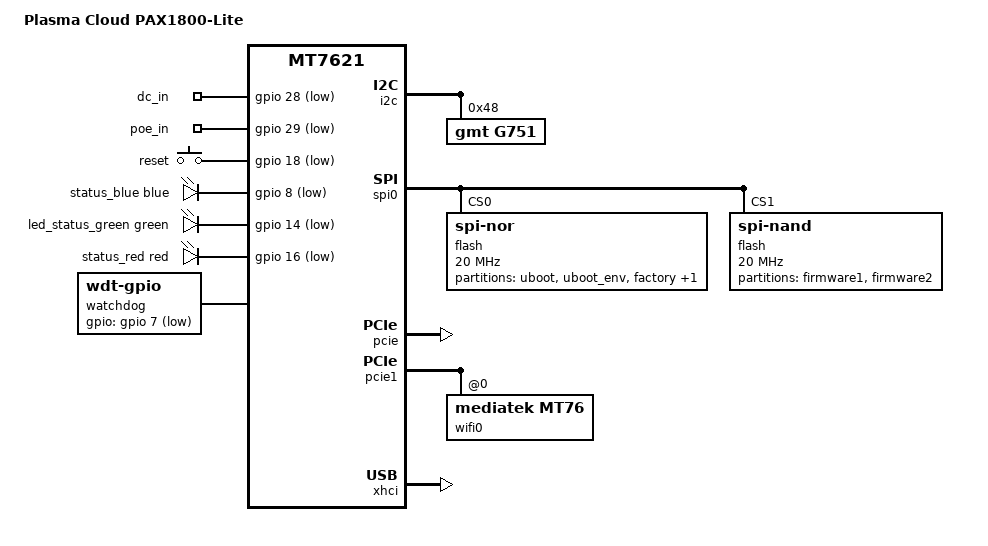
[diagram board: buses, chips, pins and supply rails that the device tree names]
// SPDX-License-Identifier: GPL-2.0-or-later OR MIT

#include "mt7621.dtsi"

#include <dt-bindings/gpio/gpio.h>
#include <dt-bindings/input/input.h>
#include <dt-bindings/leds/common.h>

/ {
	compatible = "plasmacloud,pax1800-lite", "mediatek,mt7621-soc";
	model = "Plasma Cloud PAX1800-Lite";

	chosen {
		bootargs = "console=ttyS0,115200";
	};

	aliases {
		led-boot = &led_status_green;
		led-failsafe = &led_status_green;
		led-running = &led_status_green;
		led-upgrade = &led_status_green;
		label-mac-device = &gmac1;
	};

	gpio_export {
		compatible = "gpio-export";
		#size-cells = <0>;

		dc_in {
			gpio-export,name = "dc_in";
			gpios = <&gpio 28 GPIO_ACTIVE_LOW>;
		};

		poe_in {
			gpio-export,name = "poe_in";
			gpios = <&gpio 29 GPIO_ACTIVE_LOW>;
		};
	};

	keys {
		compatible = "gpio-keys";

		reset {
			label = "reset";
			gpios = <&gpio 18 GPIO_ACTIVE_LOW>;
			linux,code = <KEY_RESTART>;
		};
	};

	leds {
		compatible = "gpio-leds";

		status_blue {
			color = <LED_COLOR_ID_BLUE>;
			function = LED_FUNCTION_STATUS;
			gpios = <&gpio 8 GPIO_ACTIVE_LOW>;
		};

		led_status_green: status_green {
			color = <LED_COLOR_ID_GREEN>;
			function = LED_FUNCTION_STATUS;
			gpios = <&gpio 14 GPIO_ACTIVE_LOW>;
		};

		status_red {
			color = <LED_COLOR_ID_RED>;
			function = LED_FUNCTION_STATUS;
			gpios = <&gpio 16 GPIO_ACTIVE_LOW>;
		};
	};

	watchdog {
		compatible = "linux,wdt-gpio";
		gpios = <&gpio 7 GPIO_ACTIVE_LOW>;
		hw_algo = "toggle";
		/* hw_margin_ms is actually 300s but driver limits it to 60s */
		hw_margin_ms = <60000>;
		always-running;
	};
};

&i2c {
	status = "okay";

	g751: g751@48 {
		compatible = "gmt,g751";
		reg = <0x48>;
		status = "okay";
	};
};

&spi0 {
	status = "okay";
	num-cs = <2>;

	flash@0 {
		#address-cells = <1>;
		#size-cells = <1>;
		compatible = "jedec,spi-nor";
		spi-max-frequency = <20000000>;
		reg = <0>;

		partitions {
			compatible = "fixed-partitions";
			#address-cells = <1>;
			#size-cells = <1>;

			partition@0 {
				label = "uboot";
				reg = <0x00000 0x80000>;
			};

			partition@80000 {
				label = "uboot_env";
				reg = <0x80000 0x10000>;
			};

			partition@90000 {
				label = "factory";
				reg = <0x90000 0x80000>;

				nvmem-layout {
					compatible = "fixed-layout";
					#address-cells = <1>;
					#size-cells = <1>;

					eeprom_factory_0: eeprom@0 {
						reg = <0x0 0xe00>;
					};

					macaddr_factory_3fff4: macaddr@3fff4 {
						reg = <0x3fff4 0x6>;
					};
				};
			};

			partition@110000 {
				label = "keys";
				reg = <0x110000 0x10000>;
			};

			/* 0x120000 - 0x200000 unused */
		};
	};

	flash@1 {
		compatible = "spi-nand";
		spi-max-frequency = <20000000>;
		reg = <1>;

		partitions {
			compatible = "fixed-partitions";
			#address-cells = <1>;
			#size-cells = <1>;

			partition@0 {
				label = "firmware1";
				reg = <0x0 0x4000000>;
				compatible = "linux,ubi";
			};

			partition@4000000 {
				label = "firmware2";
				reg = <0x4000000 0x4000000>;
				compatible = "linux,ubi";
			};
		};
	};
};

&pcie {
	status = "okay";
};

&pcie1 {
	wifi0: wifi@0,0 {
		compatible = "mediatek,mt76";
		reg = <0x0000 0 0 0 0>;

		nvmem-cells = <&eeprom_factory_0>;
		nvmem-cell-names = "eeprom";

		mediatek,disable-radar-background;

		power-limits {
			r0 {
				country = "CA";

				txpower-2g {
					b0 {
						channels = <1 1>;
						rates-cck =
							/bits/ 8 <40 40 40 40>;
						rates-ofdm =
							/bits/ 8 <36 36 36 36 36 36 36 36>;
						rates-mcs =
							/bits/ 8 <1 34 34 34 34 34 34 34 34 34 34>,
							/bits/ 8 <1 33 33 33 33 33 33 33 33 33 33>,
							/bits/ 8 <2 60 60 60 60 60 60 60 60 60 60>;
						rates-ru =
							/bits/ 8 <4 34 34 34 34 34 34 34 34 34 34 34 34>,
							/bits/ 8 <1 33 33 33 33 33 33 33 33 33 33 33 33>,
							/bits/ 8 <2 60 60 60 60 60 60 60 60 60 60 60 60>;
						paths-cck =
							/bits/ 8 <40 40 60 60>;
						paths-ofdm =
							/bits/ 8 <36 36 60 60>;
						paths-ofdm-bf =
							/bits/ 8 <36 36 60 60>;
						paths-ru =
							/bits/ 8 <4 34 34 60 60 34 60 60 60 60 60>,
							/bits/ 8 <1 33 33 60 60 33 60 60 60 60 60>,
							/bits/ 8 <2 60 60 60 60 60 60 60 60 60 60>;
						paths-ru-bf =
							/bits/ 8 <4 34 34 60 60 34 60 60 60 60 60>,
							/bits/ 8 <1 33 33 60 60 33 60 60 60 60 60>,
							/bits/ 8 <2 60 60 60 60 60 60 60 60 60 60>;
					};
					b1 {
						channels = <2 2>;
						rates-cck =
							/bits/ 8 <40 40 40 40>;
						rates-ofdm =
							/bits/ 8 <37 37 37 37 37 37 37 37>;
						rates-mcs =
							/bits/ 8 <1 34 34 34 34 34 34 34 34 34 34>,
							/bits/ 8 <1 33 33 33 33 33 33 33 33 33 33>,
							/bits/ 8 <2 60 60 60 60 60 60 60 60 60 60>;
						rates-ru =
							/bits/ 8 <4 34 34 34 34 34 34 34 34 34 34 34 34>,
							/bits/ 8 <1 33 33 33 33 33 33 33 33 33 33 33 33>,
							/bits/ 8 <2 60 60 60 60 60 60 60 60 60 60 60 60>;
						paths-cck =
							/bits/ 8 <40 40 60 60>;
						paths-ofdm =
							/bits/ 8 <37 37 60 60>;
						paths-ofdm-bf =
							/bits/ 8 <37 37 60 60>;
						paths-ru =
							/bits/ 8 <4 34 34 60 60 34 60 60 60 60 60>,
							/bits/ 8 <1 33 33 60 60 33 60 60 60 60 60>,
							/bits/ 8 <2 60 60 60 60 60 60 60 60 60 60>;
						paths-ru-bf =
							/bits/ 8 <4 34 34 60 60 34 60 60 60 60 60>,
							/bits/ 8 <1 33 33 60 60 33 60 60 60 60 60>,
							/bits/ 8 <2 60 60 60 60 60 60 60 60 60 60>;
					};
					b2 {
						channels = <3 6>;
						rates-cck =
							/bits/ 8 <40 40 40 40>;
						rates-ofdm =
							/bits/ 8 <40 40 40 40 40 40 40 40>;
						rates-mcs =
							/bits/ 8 <1 40 40 40 40 40 40 40 40 40 40>,
							/bits/ 8 <1 33 33 33 33 33 33 33 33 33 33>,
							/bits/ 8 <2 60 60 60 60 60 60 60 60 60 60>;
						rates-ru =
							/bits/ 8 <4 40 40 40 40 40 40 40 40 40 40 40 40>,
							/bits/ 8 <1 33 33 33 33 33 33 33 33 33 33 33 33>,
							/bits/ 8 <2 60 60 60 60 60 60 60 60 60 60 60 60>;
						paths-cck =
							/bits/ 8 <40 40 60 60>;
						paths-ofdm =
							/bits/ 8 <40 40 60 60>;
						paths-ofdm-bf =
							/bits/ 8 <40 40 60 60>;
						paths-ru =
							/bits/ 8 <4 40 40 60 60 40 60 60 60 60 60>,
							/bits/ 8 <1 33 33 60 60 33 60 60 60 60 60>,
							/bits/ 8 <2 60 60 60 60 60 60 60 60 60 60>;
						paths-ru-bf =
							/bits/ 8 <4 40 40 60 60 40 60 60 60 60 60>,
							/bits/ 8 <1 33 33 60 60 33 60 60 60 60 60>,
							/bits/ 8 <2 60 60 60 60 60 60 60 60 60 60>;
					};
					b3 {
						channels = <7 9>;
						rates-cck =
							/bits/ 8 <40 40 40 40>;
						rates-ofdm =
							/bits/ 8 <40 40 40 40 40 40 40 40>;
						rates-mcs =
							/bits/ 8 <1 40 40 40 40 40 40 40 40 40 40>,
							/bits/ 8 <1 32 32 32 32 32 32 32 32 32 32>,
							/bits/ 8 <2 60 60 60 60 60 60 60 60 60 60>;
						rates-ru =
							/bits/ 8 <4 40 40 40 40 40 40 40 40 40 40 40 40>,
							/bits/ 8 <1 32 32 32 32 32 32 32 32 32 32 32 32>,
							/bits/ 8 <2 60 60 60 60 60 60 60 60 60 60 60 60>;
						paths-cck =
							/bits/ 8 <40 40 60 60>;
						paths-ofdm =
							/bits/ 8 <40 40 60 60>;
						paths-ofdm-bf =
							/bits/ 8 <40 40 60 60>;
						paths-ru =
							/bits/ 8 <4 40 40 60 60 40 60 60 60 60 60>,
							/bits/ 8 <1 32 32 60 60 32 60 60 60 60 60>,
							/bits/ 8 <2 60 60 60 60 60 60 60 60 60 60>;
						paths-ru-bf =
							/bits/ 8 <4 40 40 60 60 40 60 60 60 60 60>,
							/bits/ 8 <1 32 32 60 60 32 60 60 60 60 60>,
							/bits/ 8 <2 60 60 60 60 60 60 60 60 60 60>;
					};
					b4 {
						channels = <10 10>;
						rates-cck =
							/bits/ 8 <40 40 40 40>;
						rates-ofdm =
							/bits/ 8 <38 38 38 38 38 38 38 38>;
						rates-mcs =
							/bits/ 8 <1 36 36 36 36 36 36 36 36 36 36>,
							/bits/ 8 <1 32 32 32 32 32 32 32 32 32 32>,
							/bits/ 8 <2 60 60 60 60 60 60 60 60 60 60>;
						rates-ru =
							/bits/ 8 <4 36 36 36 36 36 36 36 36 36 36 36 36>,
							/bits/ 8 <1 32 32 32 32 32 32 32 32 32 32 32 32>,
							/bits/ 8 <2 60 60 60 60 60 60 60 60 60 60 60 60>;
						paths-cck =
							/bits/ 8 <40 40 60 60>;
						paths-ofdm =
							/bits/ 8 <38 38 60 60>;
						paths-ofdm-bf =
							/bits/ 8 <38 38 60 60>;
						paths-ru =
							/bits/ 8 <4 36 36 60 60 36 60 60 60 60 60>,
							/bits/ 8 <1 32 32 60 60 32 60 60 60 60 60>,
							/bits/ 8 <2 60 60 60 60 60 60 60 60 60 60>;
						paths-ru-bf =
							/bits/ 8 <4 36 36 60 60 36 60 60 60 60 60>,
							/bits/ 8 <1 32 32 60 60 32 60 60 60 60 60>,
							/bits/ 8 <2 60 60 60 60 60 60 60 60 60 60>;
					};
					b5 {
						channels = <11 11>;
						rates-cck =
							/bits/ 8 <40 40 40 40>;
						rates-ofdm =
							/bits/ 8 <35 35 35 35 35 35 35 35>;
						rates-mcs =
							/bits/ 8 <1 33 33 33 33 33 33 33 33 33 33>,
							/bits/ 8 <1 32 32 32 32 32 32 32 32 32 32>,
							/bits/ 8 <2 60 60 60 60 60 60 60 60 60 60>;
						rates-ru =
							/bits/ 8 <4 33 33 33 33 33 33 33 33 33 33 33 33>,
							/bits/ 8 <1 32 32 32 32 32 32 32 32 32 32 32 32>,
							/bits/ 8 <2 60 60 60 60 60 60 60 60 60 60 60 60>;
						paths-cck =
							/bits/ 8 <40 40 60 60>;
						paths-ofdm =
							/bits/ 8 <35 35 60 60>;
						paths-ofdm-bf =
							/bits/ 8 <35 35 60 60>;
						paths-ru =
							/bits/ 8 <4 33 33 60 60 33 60 60 60 60 60>,
							/bits/ 8 <1 32 32 60 60 32 60 60 60 60 60>,
							/bits/ 8 <2 60 60 60 60 60 60 60 60 60 60>;
						paths-ru-bf =
							/bits/ 8 <4 33 33 60 60 33 60 60 60 60 60>,
							/bits/ 8 <1 32 32 60 60 32 60 60 60 60 60>,
							/bits/ 8 <2 60 60 60 60 60 60 60 60 60 60>;
					};
					b6 {
						channels = <12 14>;
						rates-cck =
							/bits/ 8 <60 60 60 60>;
						rates-ofdm =
							/bits/ 8 <60 60 60 60 60 60 60 60>;
						rates-mcs =
							/bits/ 8 <4 60 60 60 60 60 60 60 60 60 60>;
						rates-ru =
							/bits/ 8 <7 60 60 60 60 60 60 60 60 60 60 60 60>;
						paths-cck =
							/bits/ 8 <60 60 60 60>;
						paths-ofdm =
							/bits/ 8 <60 60 60 60>;
						paths-ofdm-bf =
							/bits/ 8 <60 60 60 60>;
						paths-ru =
							/bits/ 8 <7 60 60 60 60 60 60 60 60 60 60>;
						paths-ru-bf =
							/bits/ 8 <7 60 60 60 60 60 60 60 60 60 60>;
					};
				};
				txpower-5g {
					b0 {
						channels = <184 196>;
						rates-cck =
							/bits/ 8 <60 60 60 60>;
						rates-ofdm =
							/bits/ 8 <60 60 60 60 60 60 60 60>;
						rates-mcs =
							/bits/ 8 <4 60 60 60 60 60 60 60 60 60 60>;
						rates-ru =
							/bits/ 8 <7 60 60 60 60 60 60 60 60 60 60 60 60>;
						paths-cck =
							/bits/ 8 <60 60 60 60>;
						paths-ofdm =
							/bits/ 8 <60 60 60 60>;
						paths-ofdm-bf =
							/bits/ 8 <60 60 60 60>;
						paths-ru =
							/bits/ 8 <7 60 60 60 60 60 60 60 60 60 60>;
						paths-ru-bf =
							/bits/ 8 <7 60 60 60 60 60 60 60 60 60 60>;
					};
					b1 {
						channels = <8 16>;
						rates-cck =
							/bits/ 8 <60 60 60 60>;
						rates-ofdm =
							/bits/ 8 <60 60 60 60 60 60 60 60>;
						rates-mcs =
							/bits/ 8 <4 60 60 60 60 60 60 60 60 60 60>;
						rates-ru =
							/bits/ 8 <7 60 60 60 60 60 60 60 60 60 60 60 60>;
						paths-cck =
							/bits/ 8 <60 60 60 60>;
						paths-ofdm =
							/bits/ 8 <60 60 60 60>;
						paths-ofdm-bf =
							/bits/ 8 <60 60 60 60>;
						paths-ru =
							/bits/ 8 <7 60 60 60 60 60 60 60 60 60 60>;
						paths-ru-bf =
							/bits/ 8 <7 60 60 60 60 60 60 60 60 60 60>;
					};
					b2 {
						channels = <36 44>;
						rates-cck =
							/bits/ 8 <60 60 60 60>;
						rates-ofdm =
							/bits/ 8 <18 18 18 18 18 18 18 18>;
						rates-mcs =
							/bits/ 8 <1 20 20 20 20 20 20 20 20 20 20>,
							/bits/ 8 <1 24 24 24 24 24 24 24 24 24 24>,
							/bits/ 8 <1 25 25 25 25 25 25 25 25 25 25>,
							/bits/ 8 <1 60 60 60 60 60 60 60 60 60 60>;
						rates-ru =
							/bits/ 8 <4 20 20 20 20 20 20 20 20 20 20 20 20>,
							/bits/ 8 <1 24 24 24 24 24 24 24 24 24 24 24 24>,
							/bits/ 8 <1 25 25 25 25 25 25 25 25 25 25 25 25>,
							/bits/ 8 <1 60 60 60 60 60 60 60 60 60 60 60 60>;
						paths-cck =
							/bits/ 8 <60 60 60 60>;
						paths-ofdm =
							/bits/ 8 <18 18 60 60>;
						paths-ofdm-bf =
							/bits/ 8 <18 18 60 60>;
						paths-ru =
							/bits/ 8 <4 20 20 60 60 20 60 60 60 60 60>,
							/bits/ 8 <1 24 24 60 60 24 60 60 60 60 60>,
							/bits/ 8 <1 25 25 60 60 25 60 60 60 60 60>,
							/bits/ 8 <1 60 60 60 60 60 60 60 60 60 60>;
						paths-ru-bf =
							/bits/ 8 <4 17 17 60 60 20 60 60 60 60 60>,
							/bits/ 8 <1 18 18 60 60 24 60 60 60 60 60>,
							/bits/ 8 <1 18 18 60 60 25 60 60 60 60 60>,
							/bits/ 8 <1 60 60 60 60 60 60 60 60 60 60>;
					};
					b3 {
						channels = <48 48>;
						rates-cck =
							/bits/ 8 <60 60 60 60>;
						rates-ofdm =
							/bits/ 8 <18 18 18 18 18 18 18 18>;
						rates-mcs =
							/bits/ 8 <1 19 19 19 19 19 19 19 19 19 19>,
							/bits/ 8 <1 24 24 24 24 24 24 24 24 24 24>,
							/bits/ 8 <1 25 25 25 25 25 25 25 25 25 25>,
							/bits/ 8 <1 60 60 60 60 60 60 60 60 60 60>;
						rates-ru =
							/bits/ 8 <4 19 19 19 19 19 19 19 19 19 19 19 19>,
							/bits/ 8 <1 24 24 24 24 24 24 24 24 24 24 24 24>,
							/bits/ 8 <1 25 25 25 25 25 25 25 25 25 25 25 25>,
							/bits/ 8 <1 60 60 60 60 60 60 60 60 60 60 60 60>;
						paths-cck =
							/bits/ 8 <60 60 60 60>;
						paths-ofdm =
							/bits/ 8 <18 18 60 60>;
						paths-ofdm-bf =
							/bits/ 8 <18 18 60 60>;
						paths-ru =
							/bits/ 8 <4 19 19 60 60 19 60 60 60 60 60>,
							/bits/ 8 <1 24 24 60 60 24 60 60 60 60 60>,
							/bits/ 8 <1 25 25 60 60 25 60 60 60 60 60>,
							/bits/ 8 <1 60 60 60 60 60 60 60 60 60 60>;
						paths-ru-bf =
							/bits/ 8 <4 17 17 60 60 19 60 60 60 60 60>,
							/bits/ 8 <1 18 18 60 60 24 60 60 60 60 60>,
							/bits/ 8 <1 18 18 60 60 25 60 60 60 60 60>,
							/bits/ 8 <1 60 60 60 60 60 60 60 60 60 60>;
					};
					b4 {
						channels = <52 60>;
						rates-cck =
							/bits/ 8 <60 60 60 60>;
						rates-ofdm =
							/bits/ 8 <24 24 24 24 24 24 24 24>;
						rates-mcs =
							/bits/ 8 <3 24 24 24 24 24 24 24 24 24 24>,
							/bits/ 8 <1 60 60 60 60 60 60 60 60 60 60>;
						rates-ru =
							/bits/ 8 <6 24 24 24 24 24 24 24 24 24 24 24 24>,
							/bits/ 8 <1 60 60 60 60 60 60 60 60 60 60 60 60>;
						paths-cck =
							/bits/ 8 <60 60 60 60>;
						paths-ofdm =
							/bits/ 8 <24 24 60 60>;
						paths-ofdm-bf =
							/bits/ 8 <24 24 60 60>;
						paths-ru =
							/bits/ 8 <6 24 24 60 60 24 60 60 60 60 60>,
							/bits/ 8 <1 60 60 60 60 60 60 60 60 60 60>;
						paths-ru-bf =
							/bits/ 8 <4 18 18 60 60 24 60 60 60 60 60>,
							/bits/ 8 <1 17 17 60 60 24 60 60 60 60 60>,
							/bits/ 8 <1 18 18 60 60 24 60 60 60 60 60>,
							/bits/ 8 <1 60 60 60 60 60 60 60 60 60 60>;
					};
					b5 {
						channels = <64 64>;
						rates-cck =
							/bits/ 8 <60 60 60 60>;
						rates-ofdm =
							/bits/ 8 <24 24 24 24 24 24 24 24>;
						rates-mcs =
							/bits/ 8 <1 23 23 23 23 23 23 23 23 23 23>,
							/bits/ 8 <2 24 24 24 24 24 24 24 24 24 24>,
							/bits/ 8 <1 60 60 60 60 60 60 60 60 60 60>;
						rates-ru =
							/bits/ 8 <4 23 23 23 23 23 23 23 23 23 23 23 23>,
							/bits/ 8 <2 24 24 24 24 24 24 24 24 24 24 24 24>,
							/bits/ 8 <1 60 60 60 60 60 60 60 60 60 60 60 60>;
						paths-cck =
							/bits/ 8 <60 60 60 60>;
						paths-ofdm =
							/bits/ 8 <24 24 60 60>;
						paths-ofdm-bf =
							/bits/ 8 <24 24 60 60>;
						paths-ru =
							/bits/ 8 <4 23 23 60 60 23 60 60 60 60 60>,
							/bits/ 8 <2 24 24 60 60 24 60 60 60 60 60>,
							/bits/ 8 <1 60 60 60 60 60 60 60 60 60 60>;
						paths-ru-bf =
							/bits/ 8 <4 18 18 60 60 23 60 60 60 60 60>,
							/bits/ 8 <1 17 17 60 60 24 60 60 60 60 60>,
							/bits/ 8 <1 18 18 60 60 24 60 60 60 60 60>,
							/bits/ 8 <1 60 60 60 60 60 60 60 60 60 60>;
					};
					b6 {
						channels = <68 96>;
						rates-cck =
							/bits/ 8 <60 60 60 60>;
						rates-ofdm =
							/bits/ 8 <60 60 60 60 60 60 60 60>;
						rates-mcs =
							/bits/ 8 <4 60 60 60 60 60 60 60 60 60 60>;
						rates-ru =
							/bits/ 8 <7 60 60 60 60 60 60 60 60 60 60 60 60>;
						paths-cck =
							/bits/ 8 <60 60 60 60>;
						paths-ofdm =
							/bits/ 8 <60 60 60 60>;
						paths-ofdm-bf =
							/bits/ 8 <60 60 60 60>;
						paths-ru =
							/bits/ 8 <7 60 60 60 60 60 60 60 60 60 60>;
						paths-ru-bf =
							/bits/ 8 <7 60 60 60 60 60 60 60 60 60 60>;
					};
					b7 {
						channels = <100 100>;
						rates-cck =
							/bits/ 8 <60 60 60 60>;
						rates-ofdm =
							/bits/ 8 <32 32 32 32 32 32 32 32>;
						rates-mcs =
							/bits/ 8 <1 33 33 33 33 33 33 33 33 33 33>,
							/bits/ 8 <2 32 32 32 32 32 32 32 32 32 32>,
							/bits/ 8 <1 60 60 60 60 60 60 60 60 60 60>;
						rates-ru =
							/bits/ 8 <4 33 33 33 33 33 33 33 33 33 33 33 33>,
							/bits/ 8 <2 32 32 32 32 32 32 32 32 32 32 32 32>,
							/bits/ 8 <1 60 60 60 60 60 60 60 60 60 60 60 60>;
						paths-cck =
							/bits/ 8 <60 60 60 60>;
						paths-ofdm =
							/bits/ 8 <32 32 60 60>;
						paths-ofdm-bf =
							/bits/ 8 <32 32 60 60>;
						paths-ru =
							/bits/ 8 <4 33 33 60 60 33 60 60 60 60 60>,
							/bits/ 8 <2 32 32 60 60 32 60 60 60 60 60>,
							/bits/ 8 <1 60 60 60 60 60 60 60 60 60 60>;
						paths-ru-bf =
							/bits/ 8 <4 32 32 60 60 33 60 60 60 60 60>,
							/bits/ 8 <2 32 32 60 60 32 60 60 60 60 60>,
							/bits/ 8 <1 60 60 60 60 60 60 60 60 60 60>;
					};
					b8 {
						channels = <104 104>;
						rates-cck =
							/bits/ 8 <60 60 60 60>;
						rates-ofdm =
							/bits/ 8 <31 31 31 31 31 31 31 31>;
						rates-mcs =
							/bits/ 8 <3 32 32 32 32 32 32 32 32 32 32>,
							/bits/ 8 <1 60 60 60 60 60 60 60 60 60 60>;
						rates-ru =
							/bits/ 8 <6 32 32 32 32 32 32 32 32 32 32 32 32>,
							/bits/ 8 <1 60 60 60 60 60 60 60 60 60 60 60 60>;
						paths-cck =
							/bits/ 8 <60 60 60 60>;
						paths-ofdm =
							/bits/ 8 <31 31 60 60>;
						paths-ofdm-bf =
							/bits/ 8 <31 31 60 60>;
						paths-ru =
							/bits/ 8 <6 32 32 60 60 32 60 60 60 60 60>,
							/bits/ 8 <1 60 60 60 60 60 60 60 60 60 60>;
						paths-ru-bf =
							/bits/ 8 <6 32 32 60 60 32 60 60 60 60 60>,
							/bits/ 8 <1 60 60 60 60 60 60 60 60 60 60>;
					};
					b9 {
						channels = <108 112>;
						rates-cck =
							/bits/ 8 <60 60 60 60>;
						rates-ofdm =
							/bits/ 8 <31 31 31 31 31 31 31 31>;
						rates-mcs =
							/bits/ 8 <1 32 32 32 32 32 32 32 32 32 32>,
							/bits/ 8 <1 37 37 37 37 37 37 37 37 37 37>,
							/bits/ 8 <1 32 32 32 32 32 32 32 32 32 32>,
							/bits/ 8 <1 60 60 60 60 60 60 60 60 60 60>;
						rates-ru =
							/bits/ 8 <4 32 32 32 32 32 32 32 32 32 32 32 32>,
							/bits/ 8 <1 37 37 37 37 37 37 37 37 37 37 37 37>,
							/bits/ 8 <1 32 32 32 32 32 32 32 32 32 32 32 32>,
							/bits/ 8 <1 60 60 60 60 60 60 60 60 60 60 60 60>;
						paths-cck =
							/bits/ 8 <60 60 60 60>;
						paths-ofdm =
							/bits/ 8 <31 31 60 60>;
						paths-ofdm-bf =
							/bits/ 8 <31 31 60 60>;
						paths-ru =
							/bits/ 8 <4 32 32 60 60 32 60 60 60 60 60>,
							/bits/ 8 <1 37 37 60 60 37 60 60 60 60 60>,
							/bits/ 8 <1 32 32 60 60 32 60 60 60 60 60>,
							/bits/ 8 <1 60 60 60 60 60 60 60 60 60 60>;
						paths-ru-bf =
							/bits/ 8 <4 32 32 60 60 32 60 60 60 60 60>,
							/bits/ 8 <1 32 32 60 60 37 60 60 60 60 60>,
							/bits/ 8 <1 32 32 60 60 32 60 60 60 60 60>,
							/bits/ 8 <1 60 60 60 60 60 60 60 60 60 60>;
					};
					b10 {
						channels = <116 128>;
						rates-cck =
							/bits/ 8 <60 60 60 60>;
						rates-ofdm =
							/bits/ 8 <31 31 31 31 31 31 31 31>;
						rates-mcs =
							/bits/ 8 <1 32 32 32 32 32 32 32 32 32 32>,
							/bits/ 8 <2 37 37 37 37 37 37 37 37 37 37>,
							/bits/ 8 <1 60 60 60 60 60 60 60 60 60 60>;
						rates-ru =
							/bits/ 8 <4 32 32 32 32 32 32 32 32 32 32 32 32>,
							/bits/ 8 <2 37 37 37 37 37 37 37 37 37 37 37 37>,
							/bits/ 8 <1 60 60 60 60 60 60 60 60 60 60 60 60>;
						paths-cck =
							/bits/ 8 <60 60 60 60>;
						paths-ofdm =
							/bits/ 8 <31 31 60 60>;
						paths-ofdm-bf =
							/bits/ 8 <31 31 60 60>;
						paths-ru =
							/bits/ 8 <4 32 32 60 60 32 60 60 60 60 60>,
							/bits/ 8 <2 37 37 60 60 37 60 60 60 60 60>,
							/bits/ 8 <1 60 60 60 60 60 60 60 60 60 60>;
						paths-ru-bf =
							/bits/ 8 <4 32 32 60 60 32 60 60 60 60 60>,
							/bits/ 8 <2 32 32 60 60 37 60 60 60 60 60>,
							/bits/ 8 <1 60 60 60 60 60 60 60 60 60 60>;
					};
					b11 {
						channels = <132 136>;
						rates-cck =
							/bits/ 8 <60 60 60 60>;
						rates-ofdm =
							/bits/ 8 <31 31 31 31 31 31 31 31>;
						rates-mcs =
							/bits/ 8 <1 32 32 32 32 32 32 32 32 32 32>,
							/bits/ 8 <1 30 30 30 30 30 30 30 30 30 30>,
							/bits/ 8 <1 38 38 38 38 38 38 38 38 38 38>,
							/bits/ 8 <1 60 60 60 60 60 60 60 60 60 60>;
						rates-ru =
							/bits/ 8 <4 32 32 32 32 32 32 32 32 32 32 32 32>,
							/bits/ 8 <1 30 30 30 30 30 30 30 30 30 30 30 30>,
							/bits/ 8 <1 38 38 38 38 38 38 38 38 38 38 38 38>,
							/bits/ 8 <1 60 60 60 60 60 60 60 60 60 60 60 60>;
						paths-cck =
							/bits/ 8 <60 60 60 60>;
						paths-ofdm =
							/bits/ 8 <31 31 60 60>;
						paths-ofdm-bf =
							/bits/ 8 <31 31 60 60>;
						paths-ru =
							/bits/ 8 <4 32 32 60 60 32 60 60 60 60 60>,
							/bits/ 8 <1 30 30 60 60 30 60 60 60 60 60>,
							/bits/ 8 <1 38 38 60 60 38 60 60 60 60 60>,
							/bits/ 8 <1 60 60 60 60 60 60 60 60 60 60>;
						paths-ru-bf =
							/bits/ 8 <4 32 32 60 60 32 60 60 60 60 60>,
							/bits/ 8 <1 30 30 60 60 30 60 60 60 60 60>,
							/bits/ 8 <1 37 37 60 60 38 60 60 60 60 60>,
							/bits/ 8 <1 60 60 60 60 60 60 60 60 60 60>;
					};
					b12 {
						channels = <140 140>;
						rates-cck =
							/bits/ 8 <60 60 60 60>;
						rates-ofdm =
							/bits/ 8 <29 29 29 29 29 29 29 29>;
						rates-mcs =
							/bits/ 8 <1 32 32 32 32 32 32 32 32 32 32>,
							/bits/ 8 <1 37 37 37 37 37 37 37 37 37 37>,
							/bits/ 8 <1 38 38 38 38 38 38 38 38 38 38>,
							/bits/ 8 <1 60 60 60 60 60 60 60 60 60 60>;
						rates-ru =
							/bits/ 8 <4 32 32 32 32 32 32 32 32 32 32 32 32>,
							/bits/ 8 <1 37 37 37 37 37 37 37 37 37 37 37 37>,
							/bits/ 8 <1 38 38 38 38 38 38 38 38 38 38 38 38>,
							/bits/ 8 <1 60 60 60 60 60 60 60 60 60 60 60 60>;
						paths-cck =
							/bits/ 8 <60 60 60 60>;
						paths-ofdm =
							/bits/ 8 <29 29 60 60>;
						paths-ofdm-bf =
							/bits/ 8 <29 29 60 60>;
						paths-ru =
							/bits/ 8 <4 32 32 60 60 32 60 60 60 60 60>,
							/bits/ 8 <1 37 37 60 60 36 60 60 60 60 60>,
							/bits/ 8 <1 38 38 60 60 38 60 60 60 60 60>,
							/bits/ 8 <1 60 60 60 60 60 60 60 60 60 60>;
						paths-ru-bf =
							/bits/ 8 <4 32 32 60 60 32 60 60 60 60 60>,
							/bits/ 8 <1 32 32 60 60 37 60 60 60 60 60>,
							/bits/ 8 <1 37 37 60 60 38 60 60 60 60 60>,
							/bits/ 8 <1 60 60 60 60 60 60 60 60 60 60>;
					};
					b13 {
						channels = <144 144>;
						rates-cck =
							/bits/ 8 <60 60 60 60>;
						rates-ofdm =
							/bits/ 8 <30 30 30 30 30 30 30 30>;
						rates-mcs =
							/bits/ 8 <1 32 32 32 32 32 32 32 32 32 32>,
							/bits/ 8 <1 37 37 37 37 37 37 37 37 37 37>,
							/bits/ 8 <1 38 38 38 38 38 38 38 38 38 38>,
							/bits/ 8 <1 60 60 60 60 60 60 60 60 60 60>;
						rates-ru =
							/bits/ 8 <4 32 32 32 32 32 32 32 32 32 32 32 32>,
							/bits/ 8 <1 37 37 37 37 37 37 37 37 37 37 37 37>,
							/bits/ 8 <1 38 38 38 38 38 38 38 38 38 38 38 38>,
							/bits/ 8 <1 60 60 60 60 60 60 60 60 60 60 60 60>;
						paths-cck =
							/bits/ 8 <60 60 60 60>;
						paths-ofdm =
							/bits/ 8 <30 30 60 60>;
						paths-ofdm-bf =
							/bits/ 8 <30 30 60 60>;
						paths-ru =
							/bits/ 8 <4 32 32 60 60 32 60 60 60 60 60>,
							/bits/ 8 <1 37 37 60 60 36 60 60 60 60 60>,
							/bits/ 8 <1 38 38 60 60 38 60 60 60 60 60>,
							/bits/ 8 <1 60 60 60 60 60 60 60 60 60 60>;
						paths-ru-bf =
							/bits/ 8 <4 31 31 60 60 32 60 60 60 60 60>,
							/bits/ 8 <1 32 32 60 60 37 60 60 60 60 60>,
							/bits/ 8 <1 37 37 60 60 38 60 60 60 60 60>,
							/bits/ 8 <1 60 60 60 60 60 60 60 60 60 60>;
					};
					b14 {
						channels = <149 149>;
						rates-cck =
							/bits/ 8 <60 60 60 60>;
						rates-ofdm =
							/bits/ 8 <39 39 39 39 39 39 39 39>;
						rates-mcs =
							/bits/ 8 <2 40 40 40 40 40 40 40 40 40 40>,
							/bits/ 8 <1 38 38 38 38 38 38 38 38 38 38>,
							/bits/ 8 <1 60 60 60 60 60 60 60 60 60 60>;
						rates-ru =
							/bits/ 8 <5 40 40 40 40 40 40 40 40 40 40 40 40>,
							/bits/ 8 <1 38 38 38 38 38 38 38 38 38 38 38 38>,
							/bits/ 8 <1 60 60 60 60 60 60 60 60 60 60 60 60>;
						paths-cck =
							/bits/ 8 <60 60 60 60>;
						paths-ofdm =
							/bits/ 8 <39 39 60 60>;
						paths-ofdm-bf =
							/bits/ 8 <39 39 60 60>;
						paths-ru =
							/bits/ 8 <5 40 40 60 60 40 60 60 60 60 60>,
							/bits/ 8 <1 38 38 60 60 38 60 60 60 60 60>,
							/bits/ 8 <1 60 60 60 60 60 60 60 60 60 60>;
						paths-ru-bf =
							/bits/ 8 <5 40 40 60 60 40 60 60 60 60 60>,
							/bits/ 8 <1 38 38 60 60 38 60 60 60 60 60>,
							/bits/ 8 <1 60 60 60 60 60 60 60 60 60 60>;
					};
					b15 {
						channels = <153 161>;
						rates-cck =
							/bits/ 8 <60 60 60 60>;
						rates-ofdm =
							/bits/ 8 <40 40 40 40 40 40 40 40>;
						rates-mcs =
							/bits/ 8 <1 38 38 38 38 38 38 38 38 38 38>,
							/bits/ 8 <1 40 40 40 40 40 40 40 40 40 40>,
							/bits/ 8 <1 38 38 38 38 38 38 38 38 38 38>,
							/bits/ 8 <1 60 60 60 60 60 60 60 60 60 60>;
						rates-ru =
							/bits/ 8 <4 38 38 38 38 38 38 38 38 38 38 38 38>,
							/bits/ 8 <1 40 40 40 40 40 40 40 40 40 40 40 40>,
							/bits/ 8 <1 38 38 38 38 38 38 38 38 38 38 38 38>,
							/bits/ 8 <1 60 60 60 60 60 60 60 60 60 60 60 60>;
						paths-cck =
							/bits/ 8 <60 60 60 60>;
						paths-ofdm =
							/bits/ 8 <40 40 60 60>;
						paths-ofdm-bf =
							/bits/ 8 <40 40 60 60>;
						paths-ru =
							/bits/ 8 <4 38 38 60 60 38 60 60 60 60 60>,
							/bits/ 8 <1 40 40 60 60 40 60 60 60 60 60>,
							/bits/ 8 <1 38 38 60 60 38 60 60 60 60 60>,
							/bits/ 8 <1 60 60 60 60 60 60 60 60 60 60>;
						paths-ru-bf =
							/bits/ 8 <4 38 38 60 60 38 60 60 60 60 60>,
							/bits/ 8 <1 40 40 60 60 40 60 60 60 60 60>,
							/bits/ 8 <1 38 38 60 60 38 60 60 60 60 60>,
							/bits/ 8 <1 60 60 60 60 60 60 60 60 60 60>;
					};
					b16 {
						channels = <165 165>;
						rates-cck =
							/bits/ 8 <60 60 60 60>;
						rates-ofdm =
							/bits/ 8 <39 39 39 39 39 39 39 39>;
						rates-mcs =
							/bits/ 8 <1 38 38 38 38 38 38 38 38 38 38>,
							/bits/ 8 <3 60 60 60 60 60 60 60 60 60 60>;
						rates-ru =
							/bits/ 8 <4 38 38 38 38 38 38 38 38 38 38 38 38>,
							/bits/ 8 <3 60 60 60 60 60 60 60 60 60 60 60 60>;
						paths-cck =
							/bits/ 8 <60 60 60 60>;
						paths-ofdm =
							/bits/ 8 <39 39 60 60>;
						paths-ofdm-bf =
							/bits/ 8 <39 39 60 60>;
						paths-ru =
							/bits/ 8 <4 38 38 60 60 38 60 60 60 60 60>,
							/bits/ 8 <3 60 60 60 60 60 60 60 60 60 60>;
						paths-ru-bf =
							/bits/ 8 <4 38 38 60 60 38 60 60 60 60 60>,
							/bits/ 8 <3 60 60 60 60 60 60 60 60 60 60>;
					};
					b17 {
						channels = <169 181>;
						rates-cck =
							/bits/ 8 <60 60 60 60>;
						rates-ofdm =
							/bits/ 8 <60 60 60 60 60 60 60 60>;
						rates-mcs =
							/bits/ 8 <4 60 60 60 60 60 60 60 60 60 60>;
						rates-ru =
							/bits/ 8 <7 60 60 60 60 60 60 60 60 60 60 60 60>;
						paths-cck =
							/bits/ 8 <60 60 60 60>;
						paths-ofdm =
							/bits/ 8 <60 60 60 60>;
						paths-ofdm-bf =
							/bits/ 8 <60 60 60 60>;
						paths-ru =
							/bits/ 8 <7 60 60 60 60 60 60 60 60 60 60>;
						paths-ru-bf =
							/bits/ 8 <7 60 60 60 60 60 60 60 60 60 60>;
					};
				};
			};

			r1 {
				regdomain = "FCC";

				txpower-2g {
					b0 {
						channels = <1 1>;
						rates-cck =
							/bits/ 8 <40 40 40 40>;
						rates-ofdm =
							/bits/ 8 <36 36 36 36 36 36 36 36>;
						rates-mcs =
							/bits/ 8 <1 34 34 34 34 34 34 34 34 34 34>,
							/bits/ 8 <1 33 33 33 33 33 33 33 33 33 33>,
							/bits/ 8 <2 60 60 60 60 60 60 60 60 60 60>;
						rates-ru =
							/bits/ 8 <4 34 34 34 34 34 34 34 34 34 34 34 34>,
							/bits/ 8 <1 33 33 33 33 33 33 33 33 33 33 33 33>,
							/bits/ 8 <2 60 60 60 60 60 60 60 60 60 60 60 60>;
						paths-cck =
							/bits/ 8 <40 40 60 60>;
						paths-ofdm =
							/bits/ 8 <36 36 60 60>;
						paths-ofdm-bf =
							/bits/ 8 <36 36 60 60>;
						paths-ru =
							/bits/ 8 <4 34 34 60 60 34 60 60 60 60 60>,
							/bits/ 8 <1 33 33 60 60 33 60 60 60 60 60>,
							/bits/ 8 <2 60 60 60 60 60 60 60 60 60 60>;
						paths-ru-bf =
							/bits/ 8 <4 34 34 60 60 34 60 60 60 60 60>,
							/bits/ 8 <1 33 33 60 60 33 60 60 60 60 60>,
							/bits/ 8 <2 60 60 60 60 60 60 60 60 60 60>;
					};
					b1 {
						channels = <2 2>;
						rates-cck =
							/bits/ 8 <40 40 40 40>;
						rates-ofdm =
							/bits/ 8 <37 37 37 37 37 37 37 37>;
						rates-mcs =
							/bits/ 8 <1 34 34 34 34 34 34 34 34 34 34>,
							/bits/ 8 <1 33 33 33 33 33 33 33 33 33 33>,
							/bits/ 8 <2 60 60 60 60 60 60 60 60 60 60>;
						rates-ru =
							/bits/ 8 <4 34 34 34 34 34 34 34 34 34 34 34 34>,
							/bits/ 8 <1 33 33 33 33 33 33 33 33 33 33 33 33>,
							/bits/ 8 <2 60 60 60 60 60 60 60 60 60 60 60 60>;
						paths-cck =
							/bits/ 8 <40 40 60 60>;
						paths-ofdm =
							/bits/ 8 <37 37 60 60>;
						paths-ofdm-bf =
							/bits/ 8 <37 37 60 60>;
						paths-ru =
							/bits/ 8 <4 34 34 60 60 34 60 60 60 60 60>,
							/bits/ 8 <1 33 33 60 60 33 60 60 60 60 60>,
							/bits/ 8 <2 60 60 60 60 60 60 60 60 60 60>;
						paths-ru-bf =
							/bits/ 8 <4 34 34 60 60 34 60 60 60 60 60>,
							/bits/ 8 <1 33 33 60 60 33 60 60 60 60 60>,
							/bits/ 8 <2 60 60 60 60 60 60 60 60 60 60>;
					};
					b2 {
						channels = <3 6>;
						rates-cck =
							/bits/ 8 <40 40 40 40>;
						rates-ofdm =
							/bits/ 8 <40 40 40 40 40 40 40 40>;
						rates-mcs =
							/bits/ 8 <1 40 40 40 40 40 40 40 40 40 40>,
							/bits/ 8 <1 33 33 33 33 33 33 33 33 33 33>,
							/bits/ 8 <2 60 60 60 60 60 60 60 60 60 60>;
						rates-ru =
							/bits/ 8 <4 40 40 40 40 40 40 40 40 40 40 40 40>,
							/bits/ 8 <1 33 33 33 33 33 33 33 33 33 33 33 33>,
							/bits/ 8 <2 60 60 60 60 60 60 60 60 60 60 60 60>;
						paths-cck =
							/bits/ 8 <40 40 60 60>;
						paths-ofdm =
							/bits/ 8 <40 40 60 60>;
						paths-ofdm-bf =
							/bits/ 8 <40 40 60 60>;
						paths-ru =
							/bits/ 8 <4 40 40 60 60 40 60 60 60 60 60>,
							/bits/ 8 <1 33 33 60 60 33 60 60 60 60 60>,
							/bits/ 8 <2 60 60 60 60 60 60 60 60 60 60>;
						paths-ru-bf =
							/bits/ 8 <4 40 40 60 60 40 60 60 60 60 60>,
							/bits/ 8 <1 33 33 60 60 33 60 60 60 60 60>,
							/bits/ 8 <2 60 60 60 60 60 60 60 60 60 60>;
					};
					b3 {
						channels = <7 9>;
						rates-cck =
							/bits/ 8 <40 40 40 40>;
						rates-ofdm =
							/bits/ 8 <40 40 40 40 40 40 40 40>;
						rates-mcs =
							/bits/ 8 <1 40 40 40 40 40 40 40 40 40 40>,
							/bits/ 8 <1 32 32 32 32 32 32 32 32 32 32>,
							/bits/ 8 <2 60 60 60 60 60 60 60 60 60 60>;
						rates-ru =
							/bits/ 8 <4 40 40 40 40 40 40 40 40 40 40 40 40>,
							/bits/ 8 <1 32 32 32 32 32 32 32 32 32 32 32 32>,
							/bits/ 8 <2 60 60 60 60 60 60 60 60 60 60 60 60>;
						paths-cck =
							/bits/ 8 <40 40 60 60>;
						paths-ofdm =
							/bits/ 8 <40 40 60 60>;
						paths-ofdm-bf =
							/bits/ 8 <40 40 60 60>;
						paths-ru =
							/bits/ 8 <4 40 40 60 60 40 60 60 60 60 60>,
							/bits/ 8 <1 32 32 60 60 32 60 60 60 60 60>,
							/bits/ 8 <2 60 60 60 60 60 60 60 60 60 60>;
						paths-ru-bf =
							/bits/ 8 <4 40 40 60 60 40 60 60 60 60 60>,
							/bits/ 8 <1 32 32 60 60 32 60 60 60 60 60>,
							/bits/ 8 <2 60 60 60 60 60 60 60 60 60 60>;
					};
					b4 {
						channels = <10 10>;
						rates-cck =
							/bits/ 8 <40 40 40 40>;
						rates-ofdm =
							/bits/ 8 <38 38 38 38 38 38 38 38>;
						rates-mcs =
							/bits/ 8 <1 36 36 36 36 36 36 36 36 36 36>,
							/bits/ 8 <1 32 32 32 32 32 32 32 32 32 32>,
							/bits/ 8 <2 60 60 60 60 60 60 60 60 60 60>;
						rates-ru =
							/bits/ 8 <4 36 36 36 36 36 36 36 36 36 36 36 36>,
							/bits/ 8 <1 32 32 32 32 32 32 32 32 32 32 32 32>,
							/bits/ 8 <2 60 60 60 60 60 60 60 60 60 60 60 60>;
						paths-cck =
							/bits/ 8 <40 40 60 60>;
						paths-ofdm =
							/bits/ 8 <38 38 60 60>;
						paths-ofdm-bf =
							/bits/ 8 <38 38 60 60>;
						paths-ru =
							/bits/ 8 <4 36 36 60 60 36 60 60 60 60 60>,
							/bits/ 8 <1 32 32 60 60 32 60 60 60 60 60>,
							/bits/ 8 <2 60 60 60 60 60 60 60 60 60 60>;
						paths-ru-bf =
							/bits/ 8 <4 36 36 60 60 36 60 60 60 60 60>,
							/bits/ 8 <1 32 32 60 60 32 60 60 60 60 60>,
							/bits/ 8 <2 60 60 60 60 60 60 60 60 60 60>;
					};
					b5 {
						channels = <11 11>;
						rates-cck =
							/bits/ 8 <40 40 40 40>;
						rates-ofdm =
							/bits/ 8 <35 35 35 35 35 35 35 35>;
						rates-mcs =
							/bits/ 8 <1 33 33 33 33 33 33 33 33 33 33>,
							/bits/ 8 <1 32 32 32 32 32 32 32 32 32 32>,
							/bits/ 8 <2 60 60 60 60 60 60 60 60 60 60>;
						rates-ru =
							/bits/ 8 <4 33 33 33 33 33 33 33 33 33 33 33 33>,
							/bits/ 8 <1 32 32 32 32 32 32 32 32 32 32 32 32>,
							/bits/ 8 <2 60 60 60 60 60 60 60 60 60 60 60 60>;
						paths-cck =
							/bits/ 8 <40 40 60 60>;
						paths-ofdm =
							/bits/ 8 <35 35 60 60>;
						paths-ofdm-bf =
							/bits/ 8 <35 35 60 60>;
						paths-ru =
							/bits/ 8 <4 33 33 60 60 33 60 60 60 60 60>,
							/bits/ 8 <1 32 32 60 60 32 60 60 60 60 60>,
							/bits/ 8 <2 60 60 60 60 60 60 60 60 60 60>;
						paths-ru-bf =
							/bits/ 8 <4 33 33 60 60 33 60 60 60 60 60>,
							/bits/ 8 <1 32 32 60 60 32 60 60 60 60 60>,
							/bits/ 8 <2 60 60 60 60 60 60 60 60 60 60>;
					};
					b6 {
						channels = <12 14>;
						rates-cck =
							/bits/ 8 <60 60 60 60>;
						rates-ofdm =
							/bits/ 8 <60 60 60 60 60 60 60 60>;
						rates-mcs =
							/bits/ 8 <4 60 60 60 60 60 60 60 60 60 60>;
						rates-ru =
							/bits/ 8 <7 60 60 60 60 60 60 60 60 60 60 60 60>;
						paths-cck =
							/bits/ 8 <60 60 60 60>;
						paths-ofdm =
							/bits/ 8 <60 60 60 60>;
						paths-ofdm-bf =
							/bits/ 8 <60 60 60 60>;
						paths-ru =
							/bits/ 8 <7 60 60 60 60 60 60 60 60 60 60>;
						paths-ru-bf =
							/bits/ 8 <7 60 60 60 60 60 60 60 60 60 60>;
					};
				};
				txpower-5g {
					b0 {
						channels = <184 196>;
						rates-cck =
							/bits/ 8 <60 60 60 60>;
						rates-ofdm =
							/bits/ 8 <60 60 60 60 60 60 60 60>;
						rates-mcs =
							/bits/ 8 <4 60 60 60 60 60 60 60 60 60 60>;
						rates-ru =
							/bits/ 8 <7 60 60 60 60 60 60 60 60 60 60 60 60>;
						paths-cck =
							/bits/ 8 <60 60 60 60>;
						paths-ofdm =
							/bits/ 8 <60 60 60 60>;
						paths-ofdm-bf =
							/bits/ 8 <60 60 60 60>;
						paths-ru =
							/bits/ 8 <7 60 60 60 60 60 60 60 60 60 60>;
						paths-ru-bf =
							/bits/ 8 <7 60 60 60 60 60 60 60 60 60 60>;
					};
					b1 {
						channels = <8 16>;
						rates-cck =
							/bits/ 8 <60 60 60 60>;
						rates-ofdm =
							/bits/ 8 <60 60 60 60 60 60 60 60>;
						rates-mcs =
							/bits/ 8 <4 60 60 60 60 60 60 60 60 60 60>;
						rates-ru =
							/bits/ 8 <7 60 60 60 60 60 60 60 60 60 60 60 60>;
						paths-cck =
							/bits/ 8 <60 60 60 60>;
						paths-ofdm =
							/bits/ 8 <60 60 60 60>;
						paths-ofdm-bf =
							/bits/ 8 <60 60 60 60>;
						paths-ru =
							/bits/ 8 <7 60 60 60 60 60 60 60 60 60 60>;
						paths-ru-bf =
							/bits/ 8 <7 60 60 60 60 60 60 60 60 60 60>;
					};
					b2 {
						channels = <36 36>;
						rates-cck =
							/bits/ 8 <60 60 60 60>;
						rates-ofdm =
							/bits/ 8 <38 38 38 38 38 38 38 38>;
						rates-mcs =
							/bits/ 8 <1 37 37 37 37 37 37 37 37 37 37>,
							/bits/ 8 <1 34 34 34 34 34 34 34 34 34 34>,
							/bits/ 8 <1 28 28 28 28 28 28 28 28 28 28>,
							/bits/ 8 <1 60 60 60 60 60 60 60 60 60 60>;
						rates-ru =
							/bits/ 8 <4 37 37 37 37 37 37 37 37 37 37 37 37>,
							/bits/ 8 <1 34 34 34 34 34 34 34 34 34 34 34 34>,
							/bits/ 8 <1 28 28 28 28 28 28 28 28 28 28 28 28>,
							/bits/ 8 <1 60 60 60 60 60 60 60 60 60 60 60 60>;
						paths-cck =
							/bits/ 8 <60 60 60 60>;
						paths-ofdm =
							/bits/ 8 <38 38 60 60>;
						paths-ofdm-bf =
							/bits/ 8 <38 38 60 60>;
						paths-ru =
							/bits/ 8 <4 37 37 60 60 37 60 60 60 60 60>,
							/bits/ 8 <1 34 34 60 60 34 60 60 60 60 60>,
							/bits/ 8 <1 28 28 60 60 28 60 60 60 60 60>,
							/bits/ 8 <1 60 60 60 60 60 60 60 60 60 60>;
						paths-ru-bf =
							/bits/ 8 <4 37 37 60 60 37 60 60 60 60 60>,
							/bits/ 8 <1 34 34 60 60 34 60 60 60 60 60>,
							/bits/ 8 <1 28 28 60 60 28 60 60 60 60 60>,
							/bits/ 8 <1 60 60 60 60 60 60 60 60 60 60>;
					};
					b3 {
						channels = <40 40>;
						rates-cck =
							/bits/ 8 <60 60 60 60>;
						rates-ofdm =
							/bits/ 8 <40 40 40 40 40 40 40 40>;
						rates-mcs =
							/bits/ 8 <1 39 39 39 39 39 39 39 39 39 39>,
							/bits/ 8 <1 34 34 34 34 34 34 34 34 34 34>,
							/bits/ 8 <1 28 28 28 28 28 28 28 28 28 28>,
							/bits/ 8 <1 60 60 60 60 60 60 60 60 60 60>;
						rates-ru =
							/bits/ 8 <4 39 39 39 39 39 39 39 39 39 39 39 39>,
							/bits/ 8 <1 34 34 34 34 34 34 34 34 34 34 34 34>,
							/bits/ 8 <1 28 28 28 28 28 28 28 28 28 28 28 28>,
							/bits/ 8 <1 60 60 60 60 60 60 60 60 60 60 60 60>;
						paths-cck =
							/bits/ 8 <60 60 60 60>;
						paths-ofdm =
							/bits/ 8 <40 40 60 60>;
						paths-ofdm-bf =
							/bits/ 8 <40 40 60 60>;
						paths-ru =
							/bits/ 8 <4 39 39 60 60 39 60 60 60 60 60>,
							/bits/ 8 <1 34 34 60 60 34 60 60 60 60 60>,
							/bits/ 8 <1 28 28 60 60 28 60 60 60 60 60>,
							/bits/ 8 <1 60 60 60 60 60 60 60 60 60 60>;
						paths-ru-bf =
							/bits/ 8 <4 39 39 60 60 39 60 60 60 60 60>,
							/bits/ 8 <1 34 34 60 60 34 60 60 60 60 60>,
							/bits/ 8 <1 28 28 60 60 28 60 60 60 60 60>,
							/bits/ 8 <1 60 60 60 60 60 60 60 60 60 60>;
					};
					b4 {
						channels = <44 44>;
						rates-cck =
							/bits/ 8 <60 60 60 60>;
						rates-ofdm =
							/bits/ 8 <40 40 40 40 40 40 40 40>;
						rates-mcs =
							/bits/ 8 <2 39 39 39 39 39 39 39 39 39 39>,
							/bits/ 8 <1 28 28 28 28 28 28 28 28 28 28>,
							/bits/ 8 <1 60 60 60 60 60 60 60 60 60 60>;
						rates-ru =
							/bits/ 8 <5 39 39 39 39 39 39 39 39 39 39 39 39>,
							/bits/ 8 <1 28 28 28 28 28 28 28 28 28 28 28 28>,
							/bits/ 8 <1 60 60 60 60 60 60 60 60 60 60 60 60>;
						paths-cck =
							/bits/ 8 <60 60 60 60>;
						paths-ofdm =
							/bits/ 8 <40 40 60 60>;
						paths-ofdm-bf =
							/bits/ 8 <40 40 60 60>;
						paths-ru =
							/bits/ 8 <5 39 39 60 60 39 60 60 60 60 60>,
							/bits/ 8 <1 28 28 60 60 28 60 60 60 60 60>,
							/bits/ 8 <1 60 60 60 60 60 60 60 60 60 60>;
						paths-ru-bf =
							/bits/ 8 <5 39 39 60 60 39 60 60 60 60 60>,
							/bits/ 8 <1 28 28 60 60 28 60 60 60 60 60>,
							/bits/ 8 <1 60 60 60 60 60 60 60 60 60 60>;
					};
					b5 {
						channels = <48 48>;
						rates-cck =
							/bits/ 8 <60 60 60 60>;
						rates-ofdm =
							/bits/ 8 <40 40 40 40 40 40 40 40>;
						rates-mcs =
							/bits/ 8 <1 40 40 40 40 40 40 40 40 40 40>,
							/bits/ 8 <1 39 39 39 39 39 39 39 39 39 39>,
							/bits/ 8 <1 28 28 28 28 28 28 28 28 28 28>,
							/bits/ 8 <1 60 60 60 60 60 60 60 60 60 60>;
						rates-ru =
							/bits/ 8 <4 40 40 40 40 40 40 40 40 40 40 40 40>,
							/bits/ 8 <1 39 39 39 39 39 39 39 39 39 39 39 39>,
							/bits/ 8 <1 28 28 28 28 28 28 28 28 28 28 28 28>,
							/bits/ 8 <1 60 60 60 60 60 60 60 60 60 60 60 60>;
						paths-cck =
							/bits/ 8 <60 60 60 60>;
						paths-ofdm =
							/bits/ 8 <40 40 60 60>;
						paths-ofdm-bf =
							/bits/ 8 <40 40 60 60>;
						paths-ru =
							/bits/ 8 <4 40 40 60 60 40 60 60 60 60 60>,
							/bits/ 8 <1 39 39 60 60 39 60 60 60 60 60>,
							/bits/ 8 <1 28 28 60 60 28 60 60 60 60 60>,
							/bits/ 8 <1 60 60 60 60 60 60 60 60 60 60>;
						paths-ru-bf =
							/bits/ 8 <4 40 40 60 60 40 60 60 60 60 60>,
							/bits/ 8 <1 39 39 60 60 39 60 60 60 60 60>,
							/bits/ 8 <1 28 28 60 60 28 60 60 60 60 60>,
							/bits/ 8 <1 60 60 60 60 60 60 60 60 60 60>;
					};
					b6 {
						channels = <52 52>;
						rates-cck =
							/bits/ 8 <60 60 60 60>;
						rates-ofdm =
							/bits/ 8 <31 31 31 31 31 31 31 31>;
						rates-mcs =
							/bits/ 8 <1 33 33 33 33 33 33 33 33 33 33>,
							/bits/ 8 <1 37 37 37 37 37 37 37 37 37 37>,
							/bits/ 8 <1 28 28 28 28 28 28 28 28 28 28>,
							/bits/ 8 <1 60 60 60 60 60 60 60 60 60 60>;
						rates-ru =
							/bits/ 8 <4 33 33 33 33 33 33 33 33 33 33 33 33>,
							/bits/ 8 <1 37 37 37 37 37 37 37 37 37 37 37 37>,
							/bits/ 8 <1 28 28 28 28 28 28 28 28 28 28 28 28>,
							/bits/ 8 <1 60 60 60 60 60 60 60 60 60 60 60 60>;
						paths-cck =
							/bits/ 8 <60 60 60 60>;
						paths-ofdm =
							/bits/ 8 <31 31 60 60>;
						paths-ofdm-bf =
							/bits/ 8 <31 31 60 60>;
						paths-ru =
							/bits/ 8 <4 33 33 60 60 33 60 60 60 60 60>,
							/bits/ 8 <1 37 37 60 60 37 60 60 60 60 60>,
							/bits/ 8 <1 28 28 60 60 28 60 60 60 60 60>,
							/bits/ 8 <1 60 60 60 60 60 60 60 60 60 60>;
						paths-ru-bf =
							/bits/ 8 <4 32 32 60 60 33 60 60 60 60 60>,
							/bits/ 8 <1 31 31 60 60 37 60 60 60 60 60>,
							/bits/ 8 <1 28 28 60 60 28 60 60 60 60 60>,
							/bits/ 8 <1 60 60 60 60 60 60 60 60 60 60>;
					};
					b7 {
						channels = <56 56>;
						rates-cck =
							/bits/ 8 <60 60 60 60>;
						rates-ofdm =
							/bits/ 8 <31 31 31 31 31 31 31 31>;
						rates-mcs =
							/bits/ 8 <1 33 33 33 33 33 33 33 33 33 33>,
							/bits/ 8 <1 37 37 37 37 37 37 37 37 37 37>,
							/bits/ 8 <1 28 28 28 28 28 28 28 28 28 28>,
							/bits/ 8 <1 60 60 60 60 60 60 60 60 60 60>;
						rates-ru =
							/bits/ 8 <4 33 33 33 33 33 33 33 33 33 33 33 33>,
							/bits/ 8 <1 37 37 37 37 37 37 37 37 37 37 37 37>,
							/bits/ 8 <1 28 28 28 28 28 28 28 28 28 28 28 28>,
							/bits/ 8 <1 60 60 60 60 60 60 60 60 60 60 60 60>;
						paths-cck =
							/bits/ 8 <60 60 60 60>;
						paths-ofdm =
							/bits/ 8 <31 31 60 60>;
						paths-ofdm-bf =
							/bits/ 8 <31 31 60 60>;
						paths-ru =
							/bits/ 8 <4 33 33 60 60 33 60 60 60 60 60>,
							/bits/ 8 <1 37 37 60 60 37 60 60 60 60 60>,
							/bits/ 8 <1 28 28 60 60 28 60 60 60 60 60>,
							/bits/ 8 <1 60 60 60 60 60 60 60 60 60 60>;
						paths-ru-bf =
							/bits/ 8 <4 31 31 60 60 33 60 60 60 60 60>,
							/bits/ 8 <1 31 31 60 60 37 60 60 60 60 60>,
							/bits/ 8 <1 28 28 60 60 28 60 60 60 60 60>,
							/bits/ 8 <1 60 60 60 60 60 60 60 60 60 60>;
					};
					b8 {
						channels = <60 64>;
						rates-cck =
							/bits/ 8 <60 60 60 60>;
						rates-ofdm =
							/bits/ 8 <31 31 31 31 31 31 31 31>;
						rates-mcs =
							/bits/ 8 <1 33 33 33 33 33 33 33 33 33 33>,
							/bits/ 8 <1 32 32 32 32 32 32 32 32 32 32>,
							/bits/ 8 <1 28 28 28 28 28 28 28 28 28 28>,
							/bits/ 8 <1 60 60 60 60 60 60 60 60 60 60>;
						rates-ru =
							/bits/ 8 <4 33 33 33 33 33 33 33 33 33 33 33 33>,
							/bits/ 8 <1 32 32 32 32 32 32 32 32 32 32 32 32>,
							/bits/ 8 <1 28 28 28 28 28 28 28 28 28 28 28 28>,
							/bits/ 8 <1 60 60 60 60 60 60 60 60 60 60 60 60>;
						paths-cck =
							/bits/ 8 <60 60 60 60>;
						paths-ofdm =
							/bits/ 8 <31 31 60 60>;
						paths-ofdm-bf =
							/bits/ 8 <31 31 60 60>;
						paths-ru =
							/bits/ 8 <4 33 33 60 60 33 60 60 60 60 60>,
							/bits/ 8 <1 32 32 60 60 32 60 60 60 60 60>,
							/bits/ 8 <1 28 28 60 60 28 60 60 60 60 60>,
							/bits/ 8 <1 60 60 60 60 60 60 60 60 60 60>;
						paths-ru-bf =
							/bits/ 8 <4 31 31 60 60 33 60 60 60 60 60>,
							/bits/ 8 <1 31 31 60 60 32 60 60 60 60 60>,
							/bits/ 8 <1 28 28 60 60 28 60 60 60 60 60>,
							/bits/ 8 <1 60 60 60 60 60 60 60 60 60 60>;
					};
					b9 {
						channels = <68 96>;
						rates-cck =
							/bits/ 8 <60 60 60 60>;
						rates-ofdm =
							/bits/ 8 <60 60 60 60 60 60 60 60>;
						rates-mcs =
							/bits/ 8 <4 60 60 60 60 60 60 60 60 60 60>;
						rates-ru =
							/bits/ 8 <7 60 60 60 60 60 60 60 60 60 60 60 60>;
						paths-cck =
							/bits/ 8 <60 60 60 60>;
						paths-ofdm =
							/bits/ 8 <60 60 60 60>;
						paths-ofdm-bf =
							/bits/ 8 <60 60 60 60>;
						paths-ru =
							/bits/ 8 <7 60 60 60 60 60 60 60 60 60 60>;
						paths-ru-bf =
							/bits/ 8 <7 60 60 60 60 60 60 60 60 60 60>;
					};
					b10 {
						channels = <100 100>;
						rates-cck =
							/bits/ 8 <60 60 60 60>;
						rates-ofdm =
							/bits/ 8 <32 32 32 32 32 32 32 32>;
						rates-mcs =
							/bits/ 8 <1 33 33 33 33 33 33 33 33 33 33>,
							/bits/ 8 <2 32 32 32 32 32 32 32 32 32 32>,
							/bits/ 8 <1 60 60 60 60 60 60 60 60 60 60>;
						rates-ru =
							/bits/ 8 <4 33 33 33 33 33 33 33 33 33 33 33 33>,
							/bits/ 8 <2 32 32 32 32 32 32 32 32 32 32 32 32>,
							/bits/ 8 <1 60 60 60 60 60 60 60 60 60 60 60 60>;
						paths-cck =
							/bits/ 8 <60 60 60 60>;
						paths-ofdm =
							/bits/ 8 <32 32 60 60>;
						paths-ofdm-bf =
							/bits/ 8 <32 32 60 60>;
						paths-ru =
							/bits/ 8 <4 33 33 60 60 33 60 60 60 60 60>,
							/bits/ 8 <2 32 32 60 60 32 60 60 60 60 60>,
							/bits/ 8 <1 60 60 60 60 60 60 60 60 60 60>;
						paths-ru-bf =
							/bits/ 8 <4 32 32 60 60 33 60 60 60 60 60>,
							/bits/ 8 <2 32 32 60 60 32 60 60 60 60 60>,
							/bits/ 8 <1 60 60 60 60 60 60 60 60 60 60>;
					};
					b11 {
						channels = <104 104>;
						rates-cck =
							/bits/ 8 <60 60 60 60>;
						rates-ofdm =
							/bits/ 8 <31 31 31 31 31 31 31 31>;
						rates-mcs =
							/bits/ 8 <3 32 32 32 32 32 32 32 32 32 32>,
							/bits/ 8 <1 60 60 60 60 60 60 60 60 60 60>;
						rates-ru =
							/bits/ 8 <6 32 32 32 32 32 32 32 32 32 32 32 32>,
							/bits/ 8 <1 60 60 60 60 60 60 60 60 60 60 60 60>;
						paths-cck =
							/bits/ 8 <60 60 60 60>;
						paths-ofdm =
							/bits/ 8 <31 31 60 60>;
						paths-ofdm-bf =
							/bits/ 8 <31 31 60 60>;
						paths-ru =
							/bits/ 8 <6 32 32 60 60 32 60 60 60 60 60>,
							/bits/ 8 <1 60 60 60 60 60 60 60 60 60 60>;
						paths-ru-bf =
							/bits/ 8 <6 32 32 60 60 32 60 60 60 60 60>,
							/bits/ 8 <1 60 60 60 60 60 60 60 60 60 60>;
					};
					b12 {
						channels = <108 112>;
						rates-cck =
							/bits/ 8 <60 60 60 60>;
						rates-ofdm =
							/bits/ 8 <31 31 31 31 31 31 31 31>;
						rates-mcs =
							/bits/ 8 <1 32 32 32 32 32 32 32 32 32 32>,
							/bits/ 8 <1 37 37 37 37 37 37 37 37 37 37>,
							/bits/ 8 <1 32 32 32 32 32 32 32 32 32 32>,
							/bits/ 8 <1 60 60 60 60 60 60 60 60 60 60>;
						rates-ru =
							/bits/ 8 <4 32 32 32 32 32 32 32 32 32 32 32 32>,
							/bits/ 8 <1 37 37 37 37 37 37 37 37 37 37 37 37>,
							/bits/ 8 <1 32 32 32 32 32 32 32 32 32 32 32 32>,
							/bits/ 8 <1 60 60 60 60 60 60 60 60 60 60 60 60>;
						paths-cck =
							/bits/ 8 <60 60 60 60>;
						paths-ofdm =
							/bits/ 8 <31 31 60 60>;
						paths-ofdm-bf =
							/bits/ 8 <31 31 60 60>;
						paths-ru =
							/bits/ 8 <4 32 32 60 60 32 60 60 60 60 60>,
							/bits/ 8 <1 37 37 60 60 37 60 60 60 60 60>,
							/bits/ 8 <1 32 32 60 60 32 60 60 60 60 60>,
							/bits/ 8 <1 60 60 60 60 60 60 60 60 60 60>;
						paths-ru-bf =
							/bits/ 8 <4 32 32 60 60 32 60 60 60 60 60>,
							/bits/ 8 <1 32 32 60 60 37 60 60 60 60 60>,
							/bits/ 8 <1 32 32 60 60 32 60 60 60 60 60>,
							/bits/ 8 <1 60 60 60 60 60 60 60 60 60 60>;
					};
					b13 {
						channels = <116 128>;
						rates-cck =
							/bits/ 8 <60 60 60 60>;
						rates-ofdm =
							/bits/ 8 <31 31 31 31 31 31 31 31>;
						rates-mcs =
							/bits/ 8 <1 32 32 32 32 32 32 32 32 32 32>,
							/bits/ 8 <2 37 37 37 37 37 37 37 37 37 37>,
							/bits/ 8 <1 60 60 60 60 60 60 60 60 60 60>;
						rates-ru =
							/bits/ 8 <4 32 32 32 32 32 32 32 32 32 32 32 32>,
							/bits/ 8 <2 37 37 37 37 37 37 37 37 37 37 37 37>,
							/bits/ 8 <1 60 60 60 60 60 60 60 60 60 60 60 60>;
						paths-cck =
							/bits/ 8 <60 60 60 60>;
						paths-ofdm =
							/bits/ 8 <31 31 60 60>;
						paths-ofdm-bf =
							/bits/ 8 <31 31 60 60>;
						paths-ru =
							/bits/ 8 <4 32 32 60 60 32 60 60 60 60 60>,
							/bits/ 8 <2 37 37 60 60 37 60 60 60 60 60>,
							/bits/ 8 <1 60 60 60 60 60 60 60 60 60 60>;
						paths-ru-bf =
							/bits/ 8 <4 32 32 60 60 32 60 60 60 60 60>,
							/bits/ 8 <2 32 32 60 60 37 60 60 60 60 60>,
							/bits/ 8 <1 60 60 60 60 60 60 60 60 60 60>;
					};
					b14 {
						channels = <132 136>;
						rates-cck =
							/bits/ 8 <60 60 60 60>;
						rates-ofdm =
							/bits/ 8 <31 31 31 31 31 31 31 31>;
						rates-mcs =
							/bits/ 8 <1 32 32 32 32 32 32 32 32 32 32>,
							/bits/ 8 <1 30 30 30 30 30 30 30 30 30 30>,
							/bits/ 8 <1 38 38 38 38 38 38 38 38 38 38>,
							/bits/ 8 <1 60 60 60 60 60 60 60 60 60 60>;
						rates-ru =
							/bits/ 8 <4 32 32 32 32 32 32 32 32 32 32 32 32>,
							/bits/ 8 <1 30 30 30 30 30 30 30 30 30 30 30 30>,
							/bits/ 8 <1 38 38 38 38 38 38 38 38 38 38 38 38>,
							/bits/ 8 <1 60 60 60 60 60 60 60 60 60 60 60 60>;
						paths-cck =
							/bits/ 8 <60 60 60 60>;
						paths-ofdm =
							/bits/ 8 <31 31 60 60>;
						paths-ofdm-bf =
							/bits/ 8 <31 31 60 60>;
						paths-ru =
							/bits/ 8 <4 32 32 60 60 32 60 60 60 60 60>,
							/bits/ 8 <1 30 30 60 60 30 60 60 60 60 60>,
							/bits/ 8 <1 38 38 60 60 38 60 60 60 60 60>,
							/bits/ 8 <1 60 60 60 60 60 60 60 60 60 60>;
						paths-ru-bf =
							/bits/ 8 <4 32 32 60 60 32 60 60 60 60 60>,
							/bits/ 8 <1 30 30 60 60 30 60 60 60 60 60>,
							/bits/ 8 <1 37 37 60 60 38 60 60 60 60 60>,
							/bits/ 8 <1 60 60 60 60 60 60 60 60 60 60>;
					};
					b15 {
						channels = <140 140>;
						rates-cck =
							/bits/ 8 <60 60 60 60>;
						rates-ofdm =
							/bits/ 8 <29 29 29 29 29 29 29 29>;
						rates-mcs =
							/bits/ 8 <1 30 30 30 30 30 30 30 30 30 30>,
							/bits/ 8 <1 36 36 36 36 36 36 36 36 36 36>,
							/bits/ 8 <1 38 38 38 38 38 38 38 38 38 38>,
							/bits/ 8 <1 60 60 60 60 60 60 60 60 60 60>;
						rates-ru =
							/bits/ 8 <4 30 30 30 30 30 30 30 30 30 30 30 30>,
							/bits/ 8 <1 36 36 36 36 36 36 36 36 36 36 36 36>,
							/bits/ 8 <1 38 38 38 38 38 38 38 38 38 38 38 38>,
							/bits/ 8 <1 60 60 60 60 60 60 60 60 60 60 60 60>;
						paths-cck =
							/bits/ 8 <60 60 60 60>;
						paths-ofdm =
							/bits/ 8 <29 29 60 60>;
						paths-ofdm-bf =
							/bits/ 8 <29 29 60 60>;
						paths-ru =
							/bits/ 8 <4 30 30 60 60 30 60 60 60 60 60>,
							/bits/ 8 <1 36 36 60 60 36 60 60 60 60 60>,
							/bits/ 8 <1 38 38 60 60 38 60 60 60 60 60>,
							/bits/ 8 <1 60 60 60 60 60 60 60 60 60 60>;
						paths-ru-bf =
							/bits/ 8 <4 32 32 60 60 30 60 60 60 60 60>,
							/bits/ 8 <1 32 32 60 60 36 60 60 60 60 60>,
							/bits/ 8 <1 37 37 60 60 38 60 60 60 60 60>,
							/bits/ 8 <1 60 60 60 60 60 60 60 60 60 60>;
					};
					b16 {
						channels = <144 144>;
						rates-cck =
							/bits/ 8 <60 60 60 60>;
						rates-ofdm =
							/bits/ 8 <30 30 30 30 30 30 30 30>;
						rates-mcs =
							/bits/ 8 <1 32 32 32 32 32 32 32 32 32 32>,
							/bits/ 8 <1 36 36 36 36 36 36 36 36 36 36>,
							/bits/ 8 <1 38 38 38 38 38 38 38 38 38 38>,
							/bits/ 8 <1 60 60 60 60 60 60 60 60 60 60>;
						rates-ru =
							/bits/ 8 <4 32 32 32 32 32 32 32 32 32 32 32 32>,
							/bits/ 8 <1 36 36 36 36 36 36 36 36 36 36 36 36>,
							/bits/ 8 <1 38 38 38 38 38 38 38 38 38 38 38 38>,
							/bits/ 8 <1 60 60 60 60 60 60 60 60 60 60 60 60>;
						paths-cck =
							/bits/ 8 <60 60 60 60>;
						paths-ofdm =
							/bits/ 8 <30 30 60 60>;
						paths-ofdm-bf =
							/bits/ 8 <30 30 60 60>;
						paths-ru =
							/bits/ 8 <4 32 32 60 60 32 60 60 60 60 60>,
							/bits/ 8 <1 36 36 60 60 36 60 60 60 60 60>,
							/bits/ 8 <1 38 38 60 60 38 60 60 60 60 60>,
							/bits/ 8 <1 60 60 60 60 60 60 60 60 60 60>;
						paths-ru-bf =
							/bits/ 8 <4 32 32 60 60 32 60 60 60 60 60>,
							/bits/ 8 <1 32 32 60 60 36 60 60 60 60 60>,
							/bits/ 8 <1 37 37 60 60 38 60 60 60 60 60>,
							/bits/ 8 <1 60 60 60 60 60 60 60 60 60 60>;
					};
					b17 {
						channels = <149 149>;
						rates-cck =
							/bits/ 8 <60 60 60 60>;
						rates-ofdm =
							/bits/ 8 <39 39 39 39 39 39 39 39>;
						rates-mcs =
							/bits/ 8 <2 40 40 40 40 40 40 40 40 40 40>,
							/bits/ 8 <1 38 38 38 38 38 38 38 38 38 38>,
							/bits/ 8 <1 60 60 60 60 60 60 60 60 60 60>;
						rates-ru =
							/bits/ 8 <5 40 40 40 40 40 40 40 40 40 40 40 40>,
							/bits/ 8 <1 38 38 38 38 38 38 38 38 38 38 38 38>,
							/bits/ 8 <1 60 60 60 60 60 60 60 60 60 60 60 60>;
						paths-cck =
							/bits/ 8 <60 60 60 60>;
						paths-ofdm =
							/bits/ 8 <39 39 60 60>;
						paths-ofdm-bf =
							/bits/ 8 <39 39 60 60>;
						paths-ru =
							/bits/ 8 <5 40 40 60 60 40 60 60 60 60 60>,
							/bits/ 8 <1 38 38 60 60 38 60 60 60 60 60>,
							/bits/ 8 <1 60 60 60 60 60 60 60 60 60 60>;
						paths-ru-bf =
							/bits/ 8 <5 40 40 60 60 40 60 60 60 60 60>,
							/bits/ 8 <1 38 38 60 60 38 60 60 60 60 60>,
							/bits/ 8 <1 60 60 60 60 60 60 60 60 60 60>;
					};
					b18 {
						channels = <153 161>;
						rates-cck =
							/bits/ 8 <60 60 60 60>;
						rates-ofdm =
							/bits/ 8 <40 40 38 38 38 38 37 36>;
						rates-mcs =
							/bits/ 8 <1 38 38 38 38 38 38 38 38 38 38>,
							/bits/ 8 <1 40 40 40 40 40 40 40 40 40 40>,
							/bits/ 8 <1 38 38 38 38 38 38 38 38 38 38>,
							/bits/ 8 <1 60 60 60 60 60 60 60 60 60 60>;
						rates-ru =
							/bits/ 8 <4 38 38 38 38 38 38 38 38 38 38 38 38>,
							/bits/ 8 <1 40 40 40 40 40 40 40 40 40 40 40 40>,
							/bits/ 8 <1 38 38 38 38 38 38 38 38 38 38 38 38>,
							/bits/ 8 <1 60 60 60 60 60 60 60 60 60 60 60 60>;
						paths-cck =
							/bits/ 8 <60 60 60 60>;
						paths-ofdm =
							/bits/ 8 <40 40 60 60>;
						paths-ofdm-bf =
							/bits/ 8 <40 40 60 60>;
						paths-ru =
							/bits/ 8 <4 38 38 60 60 38 60 60 60 60 60>,
							/bits/ 8 <1 40 40 60 60 40 60 60 60 60 60>,
							/bits/ 8 <1 38 38 60 60 38 60 60 60 60 60>,
							/bits/ 8 <1 60 60 60 60 60 60 60 60 60 60>;
						paths-ru-bf =
							/bits/ 8 <4 38 38 60 60 38 60 60 60 60 60>,
							/bits/ 8 <1 40 40 60 60 40 60 60 60 60 60>,
							/bits/ 8 <1 38 38 60 60 38 60 60 60 60 60>,
							/bits/ 8 <1 60 60 60 60 60 60 60 60 60 60>;
					};
					b19 {
						channels = <165 165>;
						rates-cck =
							/bits/ 8 <60 60 60 60>;
						rates-ofdm =
							/bits/ 8 <39 39 39 39 39 39 39 39>;
						rates-mcs =
							/bits/ 8 <1 38 38 38 38 38 38 38 38 38 38>,
							/bits/ 8 <3 60 60 60 60 60 60 60 60 60 60>;
						rates-ru =
							/bits/ 8 <4 38 38 38 38 38 38 38 38 38 38 38 38>,
							/bits/ 8 <3 60 60 60 60 60 60 60 60 60 60 60 60>;
						paths-cck =
							/bits/ 8 <60 60 60 60>;
						paths-ofdm =
							/bits/ 8 <39 39 60 60>;
						paths-ofdm-bf =
							/bits/ 8 <39 39 60 60>;
						paths-ru =
							/bits/ 8 <4 38 38 60 60 38 60 60 60 60 60>,
							/bits/ 8 <3 60 60 60 60 60 60 60 60 60 60>;
						paths-ru-bf =
							/bits/ 8 <4 38 38 60 60 38 60 60 60 60 60>,
							/bits/ 8 <3 60 60 60 60 60 60 60 60 60 60>;
					};
					b20 {
						channels = <169 181>;
						rates-cck =
							/bits/ 8 <60 60 60 60>;
						rates-ofdm =
							/bits/ 8 <60 60 60 60 60 60 60 60>;
						rates-mcs =
							/bits/ 8 <4 60 60 60 60 60 60 60 60 60 60>;
						rates-ru =
							/bits/ 8 <7 60 60 60 60 60 60 60 60 60 60 60 60>;
						paths-cck =
							/bits/ 8 <60 60 60 60>;
						paths-ofdm =
							/bits/ 8 <60 60 60 60>;
						paths-ofdm-bf =
							/bits/ 8 <60 60 60 60>;
						paths-ru =
							/bits/ 8 <7 60 60 60 60 60 60 60 60 60 60>;
						paths-ru-bf =
							/bits/ 8 <7 60 60 60 60 60 60 60 60 60 60>;
					};
				};
			};

			r2 {
				regdomain = "ETSI";

				txpower-2g {
					b0 {
						channels = <1 1>;
						rates-cck =
							/bits/ 8 <24 24 24 24>;
						rates-ofdm =
							/bits/ 8 <26 26 26 26 26 26 26 26>;
						rates-mcs =
							/bits/ 8 <1 26 26 26 26 26 26 26 26 26 26>,
							/bits/ 8 <1 25 25 25 25 25 25 25 25 25 25>,
							/bits/ 8 <2 60 60 60 60 60 60 60 60 60 60>;
						rates-ru =
							/bits/ 8 <4 26 26 26 26 26 26 26 26 26 26 26 26>,
							/bits/ 8 <1 25 25 25 25 25 25 25 25 25 25 25 25>,
							/bits/ 8 <2 60 60 60 60 60 60 60 60 60 60 60 60>;
						paths-cck =
							/bits/ 8 <24 24 60 60>;
						paths-ofdm =
							/bits/ 8 <26 26 60 60>;
						paths-ofdm-bf =
							/bits/ 8 <20 20 60 60>;
						paths-ru =
							/bits/ 8 <1 26 26 60 60 26 60 60 60 60 60>,
							/bits/ 8 <1 26 26 60 60 25 60 60 60 60 60>,
							/bits/ 8 <2 26 26 60 60 26 60 60 60 60 60>,
							/bits/ 8 <1 25 25 60 60 25 60 60 60 60 60>,
							/bits/ 8 <2 60 60 60 60 60 60 60 60 60 60>;
						paths-ru-bf =
							/bits/ 8 <5 19 19 60 60 25 60 60 60 60 60>,
							/bits/ 8 <2 60 60 60 60 60 60 60 60 60 60>;
					};
					b1 {
						channels = <2 12>;
						rates-cck =
							/bits/ 8 <24 24 24 24>;
						rates-ofdm =
							/bits/ 8 <25 25 25 25 25 25 25 25>;
						rates-mcs =
							/bits/ 8 <2 25 25 25 25 25 25 25 25 25 25>,
							/bits/ 8 <2 60 60 60 60 60 60 60 60 60 60>;
						rates-ru =
							/bits/ 8 <5 25 25 25 25 25 25 25 25 25 25 25 25>,
							/bits/ 8 <2 60 60 60 60 60 60 60 60 60 60 60 60>;
						paths-cck =
							/bits/ 8 <24 24 60 60>;
						paths-ofdm =
							/bits/ 8 <25 25 60 60>;
						paths-ofdm-bf =
							/bits/ 8 <19 19 60 60>;
						paths-ru =
							/bits/ 8 <5 25 25 60 60 25 60 60 60 60 60>,
							/bits/ 8 <2 60 60 60 60 60 60 60 60 60 60>;
						paths-ru-bf =
							/bits/ 8 <4 20 20 60 60 26 60 60 60 60 60>,
							/bits/ 8 <1 19 19 60 60 25 60 60 60 60 60>,
							/bits/ 8 <2 60 60 60 60 60 60 60 60 60 60>;
					};
					b2 {
						channels = <13 13>;
						rates-cck =
							/bits/ 8 <24 24 24 24>;
						rates-ofdm =
							/bits/ 8 <25 25 25 25 25 25 25 25>;
						rates-mcs =
							/bits/ 8 <1 26 26 26 26 26 26 26 26 26 26>,
							/bits/ 8 <1 25 25 25 25 25 25 25 25 25 25>,
							/bits/ 8 <2 60 60 60 60 60 60 60 60 60 60>;
						rates-ru =
							/bits/ 8 <4 26 26 26 26 26 26 26 26 26 26 26 26>,
							/bits/ 8 <1 25 25 25 25 25 25 25 25 25 25 25 25>,
							/bits/ 8 <2 60 60 60 60 60 60 60 60 60 60 60 60>;
						paths-cck =
							/bits/ 8 <24 24 60 60>;
						paths-ofdm =
							/bits/ 8 <25 25 60 60>;
						paths-ofdm-bf =
							/bits/ 8 <19 19 60 60>;
						paths-ru =
							/bits/ 8 <1 26 26 60 60 26 60 60 60 60 60>,
							/bits/ 8 <1 26 26 60 60 25 60 60 60 60 60>,
							/bits/ 8 <2 26 26 60 60 26 60 60 60 60 60>,
							/bits/ 8 <1 25 25 60 60 25 60 60 60 60 60>,
							/bits/ 8 <2 60 60 60 60 60 60 60 60 60 60>;
						paths-ru-bf =
							/bits/ 8 <4 20 20 60 60 26 60 60 60 60 60>,
							/bits/ 8 <1 19 19 60 60 25 60 60 60 60 60>,
							/bits/ 8 <2 60 60 60 60 60 60 60 60 60 60>;
					};
					b3 {
						channels = <14 14>;
						rates-cck =
							/bits/ 8 <60 60 60 60>;
						rates-ofdm =
							/bits/ 8 <60 60 60 60 60 60 60 60>;
						rates-mcs =
							/bits/ 8 <4 60 60 60 60 60 60 60 60 60 60>;
						rates-ru =
							/bits/ 8 <7 60 60 60 60 60 60 60 60 60 60 60 60>;
						paths-cck =
							/bits/ 8 <60 60 60 60>;
						paths-ofdm =
							/bits/ 8 <60 60 60 60>;
						paths-ofdm-bf =
							/bits/ 8 <60 60 60 60>;
						paths-ru =
							/bits/ 8 <7 60 60 60 60 60 60 60 60 60 60>;
						paths-ru-bf =
							/bits/ 8 <7 60 60 60 60 60 60 60 60 60 60>;
					};
				};
				txpower-5g {
					b0 {
						channels = <184 196>;
						rates-cck =
							/bits/ 8 <60 60 60 60>;
						rates-ofdm =
							/bits/ 8 <60 60 60 60 60 60 60 60>;
						rates-mcs =
							/bits/ 8 <4 60 60 60 60 60 60 60 60 60 60>;
						rates-ru =
							/bits/ 8 <7 60 60 60 60 60 60 60 60 60 60 60 60>;
						paths-cck =
							/bits/ 8 <60 60 60 60>;
						paths-ofdm =
							/bits/ 8 <60 60 60 60>;
						paths-ofdm-bf =
							/bits/ 8 <60 60 60 60>;
						paths-ru =
							/bits/ 8 <7 60 60 60 60 60 60 60 60 60 60>;
						paths-ru-bf =
							/bits/ 8 <7 60 60 60 60 60 60 60 60 60 60>;
					};
					b1 {
						channels = <8 16>;
						rates-cck =
							/bits/ 8 <60 60 60 60>;
						rates-ofdm =
							/bits/ 8 <60 60 60 60 60 60 60 60>;
						rates-mcs =
							/bits/ 8 <4 60 60 60 60 60 60 60 60 60 60>;
						rates-ru =
							/bits/ 8 <7 60 60 60 60 60 60 60 60 60 60 60 60>;
						paths-cck =
							/bits/ 8 <60 60 60 60>;
						paths-ofdm =
							/bits/ 8 <60 60 60 60>;
						paths-ofdm-bf =
							/bits/ 8 <60 60 60 60>;
						paths-ru =
							/bits/ 8 <7 60 60 60 60 60 60 60 60 60 60>;
						paths-ru-bf =
							/bits/ 8 <7 60 60 60 60 60 60 60 60 60 60>;
					};
					b2 {
						channels = <36 48>;
						rates-cck =
							/bits/ 8 <60 60 60 60>;
						rates-ofdm =
							/bits/ 8 <24 24 24 24 24 24 24 24>;
						rates-mcs =
							/bits/ 8 <1 24 24 24 24 24 24 24 24 24 24>,
							/bits/ 8 <2 25 25 25 25 25 25 25 25 25 25>,
							/bits/ 8 <1 60 60 60 60 60 60 60 60 60 60>;
						rates-ru =
							/bits/ 8 <4 24 24 24 24 24 24 24 24 24 24 24 24>,
							/bits/ 8 <2 25 25 25 25 25 25 25 25 25 25 25 25>,
							/bits/ 8 <1 60 60 60 60 60 60 60 60 60 60 60 60>;
						paths-cck =
							/bits/ 8 <60 60 60 60>;
						paths-ofdm =
							/bits/ 8 <24 24 60 60>;
						paths-ofdm-bf =
							/bits/ 8 <18 18 60 60>;
						paths-ru =
							/bits/ 8 <4 24 24 60 60 24 60 60 60 60 60>,
							/bits/ 8 <2 25 25 60 60 25 60 60 60 60 60>,
							/bits/ 8 <1 60 60 60 60 60 60 60 60 60 60>;
						paths-ru-bf =
							/bits/ 8 <6 19 19 60 60 25 60 60 60 60 60>,
							/bits/ 8 <1 60 60 60 60 60 60 60 60 60 60>;
					};
					b3 {
						channels = <52 64>;
						rates-cck =
							/bits/ 8 <60 60 60 60>;
						rates-ofdm =
							/bits/ 8 <23 23 25 25 25 25 25 25>;
						rates-mcs =
							/bits/ 8 <1 24 24 24 24 24 24 24 24 24 24>,
							/bits/ 8 <1 25 25 25 25 25 25 25 25 25 25>,
							/bits/ 8 <1 24 24 24 24 24 24 24 24 24 24>,
							/bits/ 8 <1 60 60 60 60 60 60 60 60 60 60>;
						rates-ru =
							/bits/ 8 <4 24 24 24 24 24 24 24 24 24 24 24 24>,
							/bits/ 8 <1 25 25 25 25 25 25 25 25 25 25 25 25>,
							/bits/ 8 <1 24 24 24 24 24 24 24 24 24 24 24 24>,
							/bits/ 8 <1 60 60 60 60 60 60 60 60 60 60 60 60>;
						paths-cck =
							/bits/ 8 <60 60 60 60>;
						paths-ofdm =
							/bits/ 8 <23 23 60 60>;
						paths-ofdm-bf =
							/bits/ 8 <17 17 60 60>;
						paths-ru =
							/bits/ 8 <4 24 24 60 60 24 60 60 60 60 60>,
							/bits/ 8 <1 25 25 60 60 25 60 60 60 60 60>,
							/bits/ 8 <1 24 24 60 60 24 60 60 60 60 60>,
							/bits/ 8 <1 60 60 60 60 60 60 60 60 60 60>;
						paths-ru-bf =
							/bits/ 8 <4 18 18 60 60 24 60 60 60 60 60>,
							/bits/ 8 <1 19 19 60 60 25 60 60 60 60 60>,
							/bits/ 8 <1 18 18 60 60 24 60 60 60 60 60>,
							/bits/ 8 <1 60 60 60 60 60 60 60 60 60 60>;
					};
					b4 {
						channels = <68 96>;
						rates-cck =
							/bits/ 8 <60 60 60 60>;
						rates-ofdm =
							/bits/ 8 <60 60 60 60 60 60 60 60>;
						rates-mcs =
							/bits/ 8 <4 60 60 60 60 60 60 60 60 60 60>;
						rates-ru =
							/bits/ 8 <7 60 60 60 60 60 60 60 60 60 60 60 60>;
						paths-cck =
							/bits/ 8 <60 60 60 60>;
						paths-ofdm =
							/bits/ 8 <60 60 60 60>;
						paths-ofdm-bf =
							/bits/ 8 <60 60 60 60>;
						paths-ru =
							/bits/ 8 <7 60 60 60 60 60 60 60 60 60 60>;
						paths-ru-bf =
							/bits/ 8 <7 60 60 60 60 60 60 60 60 60 60>;
					};
					b5 {
						channels = <100 128>;
						rates-cck =
							/bits/ 8 <60 60 60 60>;
						rates-ofdm =
							/bits/ 8 <38 38 38 38 38 38 38 38>;
						rates-mcs =
							/bits/ 8 <1 38 38 38 38 38 38 38 38 38 38>,
							/bits/ 8 <1 39 39 39 39 39 39 39 39 39 39>,
							/bits/ 8 <1 38 38 38 38 38 38 38 38 38 38>,
							/bits/ 8 <1 60 60 60 60 60 60 60 60 60 60>;
						rates-ru =
							/bits/ 8 <4 38 38 38 38 38 38 38 38 38 38 38 38>,
							/bits/ 8 <1 39 39 39 39 39 39 39 39 39 39 39 39>,
							/bits/ 8 <1 38 38 38 38 38 38 38 38 38 38 38 38>,
							/bits/ 8 <1 60 60 60 60 60 60 60 60 60 60 60 60>;
						paths-cck =
							/bits/ 8 <60 60 60 60>;
						paths-ofdm =
							/bits/ 8 <38 38 60 60>;
						paths-ofdm-bf =
							/bits/ 8 <32 32 60 60>;
						paths-ru =
							/bits/ 8 <4 38 38 60 60 38 60 60 60 60 60>,
							/bits/ 8 <1 39 39 60 60 39 60 60 60 60 60>,
							/bits/ 8 <1 38 38 60 60 38 60 60 60 60 60>,
							/bits/ 8 <1 60 60 60 60 60 60 60 60 60 60>;
						paths-ru-bf =
							/bits/ 8 <4 33 33 60 60 39 60 60 60 60 60>,
							/bits/ 8 <2 32 32 60 60 38 60 60 60 60 60>,
							/bits/ 8 <1 60 60 60 60 60 60 60 60 60 60>;
					};
					b6 {
						channels = <132 136>;
						rates-cck =
							/bits/ 8 <60 60 60 60>;
						rates-ofdm =
							/bits/ 8 <38 38 38 38 38 38 38 38>;
						rates-mcs =
							/bits/ 8 <1 38 38 38 38 38 38 38 38 38 38>,
							/bits/ 8 <1 39 39 39 39 39 39 39 39 39 39>,
							/bits/ 8 <2 60 60 60 60 60 60 60 60 60 60>;
						rates-ru =
							/bits/ 8 <4 38 38 38 38 38 38 38 38 38 38 38 38>,
							/bits/ 8 <1 39 39 39 39 39 39 39 39 39 39 39 39>,
							/bits/ 8 <2 60 60 60 60 60 60 60 60 60 60 60 60>;
						paths-cck =
							/bits/ 8 <60 60 60 60>;
						paths-ofdm =
							/bits/ 8 <38 38 60 60>;
						paths-ofdm-bf =
							/bits/ 8 <32 32 60 60>;
						paths-ru =
							/bits/ 8 <4 38 38 60 60 38 60 60 60 60 60>,
							/bits/ 8 <1 39 39 60 60 39 60 60 60 60 60>,
							/bits/ 8 <2 60 60 60 60 60 60 60 60 60 60>;
						paths-ru-bf =
							/bits/ 8 <4 33 33 60 60 39 60 60 60 60 60>,
							/bits/ 8 <1 32 32 60 60 38 60 60 60 60 60>,
							/bits/ 8 <2 60 60 60 60 60 60 60 60 60 60>;
					};
					b7 {
						channels = <140 140>;
						rates-cck =
							/bits/ 8 <60 60 60 60>;
						rates-ofdm =
							/bits/ 8 <37 37 37 37 37 37 37 37>;
						rates-mcs =
							/bits/ 8 <1 38 38 38 38 38 38 38 38 38 38>,
							/bits/ 8 <3 60 60 60 60 60 60 60 60 60 60>;
						rates-ru =
							/bits/ 8 <4 38 38 38 38 38 38 38 38 38 38 38 38>,
							/bits/ 8 <3 60 60 60 60 60 60 60 60 60 60 60 60>;
						paths-cck =
							/bits/ 8 <60 60 60 60>;
						paths-ofdm =
							/bits/ 8 <37 37 60 60>;
						paths-ofdm-bf =
							/bits/ 8 <31 31 60 60>;
						paths-ru =
							/bits/ 8 <4 38 38 60 60 38 60 60 60 60 60>,
							/bits/ 8 <3 60 60 60 60 60 60 60 60 60 60>;
						paths-ru-bf =
							/bits/ 8 <4 33 33 60 60 39 60 60 60 60 60>,
							/bits/ 8 <3 60 60 60 60 60 60 60 60 60 60>;
					};
					b8 {
						channels = <144 144>;
						rates-cck =
							/bits/ 8 <60 60 60 60>;
						rates-ofdm =
							/bits/ 8 <60 60 60 60 60 60 60 60>;
						rates-mcs =
							/bits/ 8 <4 60 60 60 60 60 60 60 60 60 60>;
						rates-ru =
							/bits/ 8 <7 60 60 60 60 60 60 60 60 60 60 60 60>;
						paths-cck =
							/bits/ 8 <60 60 60 60>;
						paths-ofdm =
							/bits/ 8 <60 60 60 60>;
						paths-ofdm-bf =
							/bits/ 8 <60 60 60 60>;
						paths-ru =
							/bits/ 8 <7 60 60 60 60 60 60 60 60 60 60>;
						paths-ru-bf =
							/bits/ 8 <7 60 60 60 60 60 60 60 60 60 60>;
					};
					b9 {
						channels = <149 149>;
						rates-cck =
							/bits/ 8 <60 60 60 60>;
						rates-ofdm =
							/bits/ 8 <39 39 39 39 39 39 39 39>;
						rates-mcs =
							/bits/ 8 <2 40 40 40 40 40 40 40 40 40 40>,
							/bits/ 8 <1 38 38 38 38 38 38 38 38 38 38>,
							/bits/ 8 <1 60 60 60 60 60 60 60 60 60 60>;
						rates-ru =
							/bits/ 8 <5 40 40 40 40 40 40 40 40 40 40 40 40>,
							/bits/ 8 <1 38 38 38 38 38 38 38 38 38 38 38 38>,
							/bits/ 8 <1 60 60 60 60 60 60 60 60 60 60 60 60>;
						paths-cck =
							/bits/ 8 <60 60 60 60>;
						paths-ofdm =
							/bits/ 8 <39 39 60 60>;
						paths-ofdm-bf =
							/bits/ 8 <39 39 60 60>;
						paths-ru =
							/bits/ 8 <5 40 40 60 60 40 60 60 60 60 60>,
							/bits/ 8 <1 38 38 60 60 38 60 60 60 60 60>,
							/bits/ 8 <1 60 60 60 60 60 60 60 60 60 60>;
						paths-ru-bf =
							/bits/ 8 <5 40 40 60 60 40 60 60 60 60 60>,
							/bits/ 8 <1 38 38 60 60 38 60 60 60 60 60>,
							/bits/ 8 <1 60 60 60 60 60 60 60 60 60 60>;
					};
					b10 {
						channels = <153 161>;
						rates-cck =
							/bits/ 8 <60 60 60 60>;
						rates-ofdm =
							/bits/ 8 <40 40 38 38 38 38 37 36>;
						rates-mcs =
							/bits/ 8 <1 38 38 38 38 38 38 38 38 38 38>,
							/bits/ 8 <1 40 40 40 40 40 40 40 40 40 40>,
							/bits/ 8 <1 38 38 38 38 38 38 38 38 38 38>,
							/bits/ 8 <1 60 60 60 60 60 60 60 60 60 60>;
						rates-ru =
							/bits/ 8 <4 38 38 38 38 38 38 38 38 38 38 38 38>,
							/bits/ 8 <1 40 40 40 40 40 40 40 40 40 40 40 40>,
							/bits/ 8 <1 38 38 38 38 38 38 38 38 38 38 38 38>,
							/bits/ 8 <1 60 60 60 60 60 60 60 60 60 60 60 60>;
						paths-cck =
							/bits/ 8 <60 60 60 60>;
						paths-ofdm =
							/bits/ 8 <40 40 60 60>;
						paths-ofdm-bf =
							/bits/ 8 <40 40 60 60>;
						paths-ru =
							/bits/ 8 <4 38 38 60 60 38 60 60 60 60 60>,
							/bits/ 8 <1 40 40 60 60 40 60 60 60 60 60>,
							/bits/ 8 <1 38 38 60 60 38 60 60 60 60 60>,
							/bits/ 8 <1 60 60 60 60 60 60 60 60 60 60>;
						paths-ru-bf =
							/bits/ 8 <4 38 38 60 60 38 60 60 60 60 60>,
							/bits/ 8 <1 40 40 60 60 40 60 60 60 60 60>,
							/bits/ 8 <1 38 38 60 60 38 60 60 60 60 60>,
							/bits/ 8 <1 60 60 60 60 60 60 60 60 60 60>;
					};
					b11 {
						channels = <165 165>;
						rates-cck =
							/bits/ 8 <60 60 60 60>;
						rates-ofdm =
							/bits/ 8 <39 39 39 39 39 39 39 39>;
						rates-mcs =
							/bits/ 8 <1 38 38 38 38 38 38 38 38 38 38>,
							/bits/ 8 <3 60 60 60 60 60 60 60 60 60 60>;
						rates-ru =
							/bits/ 8 <4 38 38 38 38 38 38 38 38 38 38 38 38>,
							/bits/ 8 <3 60 60 60 60 60 60 60 60 60 60 60 60>;
						paths-cck =
							/bits/ 8 <60 60 60 60>;
						paths-ofdm =
							/bits/ 8 <39 39 60 60>;
						paths-ofdm-bf =
							/bits/ 8 <39 39 60 60>;
						paths-ru =
							/bits/ 8 <4 38 38 60 60 38 60 60 60 60 60>,
							/bits/ 8 <3 60 60 60 60 60 60 60 60 60 60>;
						paths-ru-bf =
							/bits/ 8 <4 38 38 60 60 38 60 60 60 60 60>,
							/bits/ 8 <3 60 60 60 60 60 60 60 60 60 60>;
					};
					b12 {
						channels = <169 169>;
						rates-cck =
							/bits/ 8 <60 60 60 60>;
						rates-ofdm =
							/bits/ 8 <39 39 39 39 39 39 39 39>;
						rates-mcs =
							/bits/ 8 <1 38 38 38 38 38 38 38 38 38 38>,
							/bits/ 8 <3 60 60 60 60 60 60 60 60 60 60>;
						rates-ru =
							/bits/ 8 <4 38 38 38 38 38 38 38 38 38 38 38 38>,
							/bits/ 8 <3 60 60 60 60 60 60 60 60 60 60 60 60>;
						paths-cck =
							/bits/ 8 <60 60 60 60>;
						paths-ofdm =
							/bits/ 8 <60 60 60 60>;
						paths-ofdm-bf =
							/bits/ 8 <60 60 60 60>;
						paths-ru =
							/bits/ 8 <7 60 60 60 60 60 60 60 60 60 60>;
						paths-ru-bf =
							/bits/ 8 <7 60 60 60 60 60 60 60 60 60 60>;
					};
					b13 {
						channels = <173 181>;
						rates-cck =
							/bits/ 8 <60 60 60 60>;
						rates-ofdm =
							/bits/ 8 <60 60 60 60 60 60 60 60>;
						rates-mcs =
							/bits/ 8 <4 60 60 60 60 60 60 60 60 60 60>;
						rates-ru =
							/bits/ 8 <7 60 60 60 60 60 60 60 60 60 60 60 60>;
						paths-cck =
							/bits/ 8 <60 60 60 60>;
						paths-ofdm =
							/bits/ 8 <60 60 60 60>;
						paths-ofdm-bf =
							/bits/ 8 <60 60 60 60>;
						paths-ru =
							/bits/ 8 <7 60 60 60 60 60 60 60 60 60 60>;
						paths-ru-bf =
							/bits/ 8 <7 60 60 60 60 60 60 60 60 60 60>;
					};
				};
			};
		};
	};
};

&xhci {
	status = "okay";
};

&ethernet {
	pinctrl-0 = <&mdio_pins>;
};

&gmac0 {
	nvmem-cells = <&macaddr_factory_3fff4 0>;
	nvmem-cell-names = "mac-address";
	label = "dsa";
};

&switch0 {
	ports {
		port@4 {
			status = "okay";
			label = "lan";
		};
	};
};

&state_default {
	gpio {
		/* for LEDs + Button + watchdog */
		groups = "uart3", "jtag", "wdt", "rgmii2";
		function = "gpio";
	};
};
